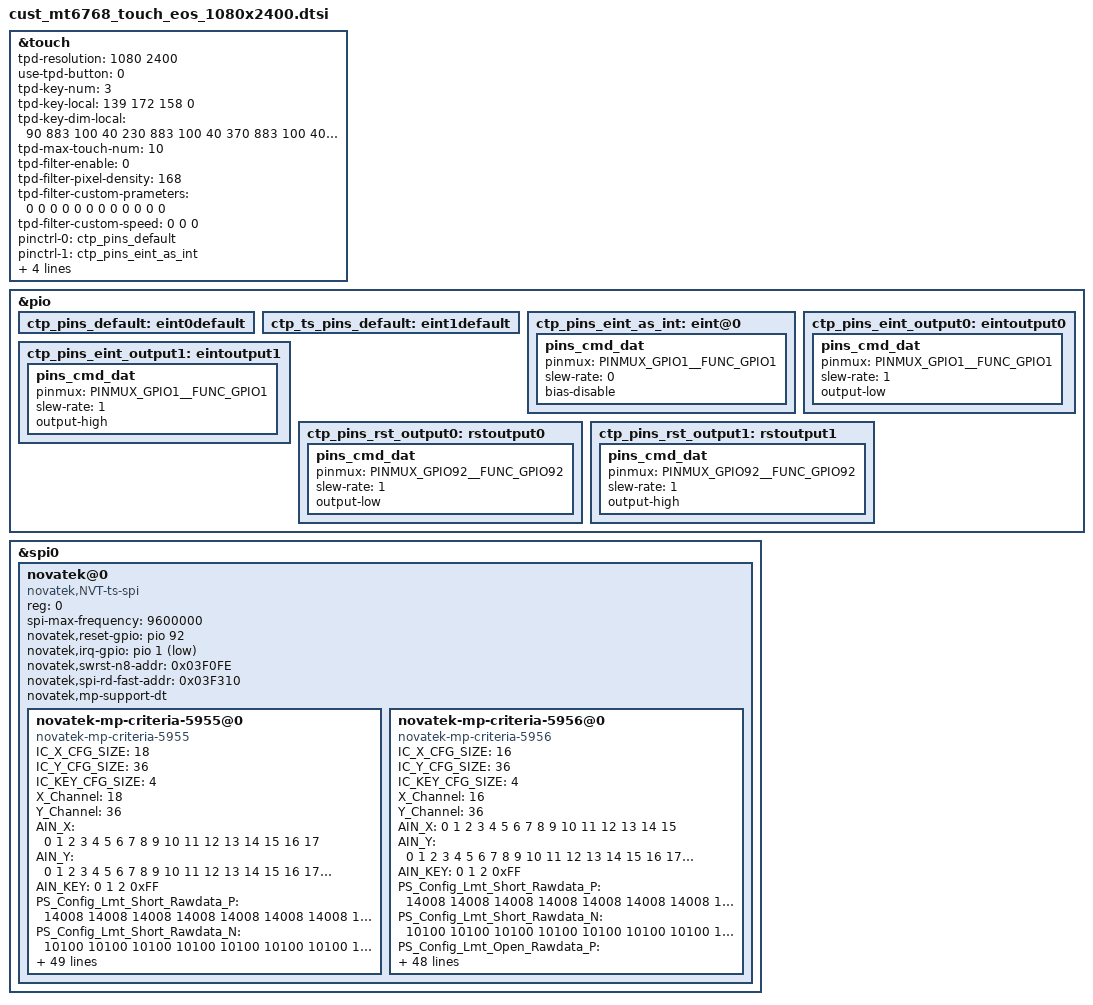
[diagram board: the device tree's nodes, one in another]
/*
 * Copyright (c) 2019 MediaTek Inc.
 *
 * This program is free software; you can redistribute it and/or modify
 * it under the terms of the GNU General Public License version 2 as
 * published by the Free Software Foundation.
 *
 * This program is distributed in the hope that it will be useful,
 * but WITHOUT ANY WARRANTY; without even the implied warranty of
 * MERCHANTABILITY or FITNESS FOR A PARTICULAR PURPOSE.  See the
 * GNU General Public License for more details.
 */
/* TOUCH start */

&touch {
	tpd-resolution = <1080 2400>;
	use-tpd-button = <0>;
	tpd-key-num = <3>;
	tpd-key-local= <139 172 158 0>;
	tpd-key-dim-local = <90 883 100 40 230
				883 100 40 370 883 100 40 0 0 0 0>;
	tpd-max-touch-num = <10>;
	tpd-filter-enable = <0>;
	tpd-filter-pixel-density = <168>;
	tpd-filter-custom-prameters = <0 0 0 0 0 0 0 0 0 0 0 0>;
	tpd-filter-custom-speed = <0 0 0>;
	pinctrl-names = "default", "state_eint_as_int",
		"state_eint_output0", "state_eint_output1",
		"state_rst_output0", "state_rst_output1";
	pinctrl-0 = <&ctp_pins_default>;
	pinctrl-1 = <&ctp_pins_eint_as_int>;
	pinctrl-2 = <&ctp_pins_eint_output0>;
	pinctrl-3 = <&ctp_pins_eint_output1>;
	pinctrl-4 = <&ctp_pins_rst_output0>;
	pinctrl-5 = <&ctp_pins_rst_output1>;
	status = "okay";
};
&pio {
	ctp_pins_default: eint0default {
	};
	ctp_ts_pins_default: eint1default {
	};
	ctp_pins_eint_as_int: eint@0 {
		pins_cmd_dat {
			pinmux = <PINMUX_GPIO1__FUNC_GPIO1>;
			slew-rate = <0>;
			bias-disable;
		};
	};
	ctp_pins_eint_output0: eintoutput0 {
		pins_cmd_dat {
			pinmux = <PINMUX_GPIO1__FUNC_GPIO1>;
			slew-rate = <1>;
			output-low;
		};
	};
	ctp_pins_eint_output1: eintoutput1 {
		pins_cmd_dat {
			pinmux = <PINMUX_GPIO1__FUNC_GPIO1>;
			slew-rate = <1>;
			output-high;
	};
	};
	ctp_pins_rst_output0: rstoutput0 {
		pins_cmd_dat {
				pinmux = <PINMUX_GPIO92__FUNC_GPIO92>;
				slew-rate = <1>;
				output-low;
			};
	};
	ctp_pins_rst_output1: rstoutput1 {
		pins_cmd_dat {
				pinmux = <PINMUX_GPIO92__FUNC_GPIO92>;
				slew-rate = <1>;
				output-high;
		};
	};

};

&spi0 {
	novatek@0 {
		compatible = "novatek,NVT-ts-spi","focaltech8719P,FTS-ts-spi";
		reg = <0>; //Same as CS ID
		status = "ok";

		spi-max-frequency = <9600000>;	//4800000,9600000,15000000,19200000
		novatek,reset-gpio = <&pio 92 0x00>;
		novatek,irq-gpio = <&pio 1 0x2001>;

		/* 525 */
		//novatek,swrst-n8-addr = <0x01F01A>;

		/* 672A, 525B, 675, 526, 672C */
		novatek,swrst-n8-addr = <0x03F0FE>;
		novatek,spi-rd-fast-addr = <0x03F310>;

		/* MP */
		novatek,mp-support-dt;

		/*for Xiaomi K19A 672C TM6.497" Module*/
		novatek-mp-criteria-5955@0 {
			#address-cells = <1>;
			#size-cells = <0>;
			compatible = "novatek-mp-criteria-5955";

			/* MP Config */
			IC_X_CFG_SIZE = <18>;
			IC_Y_CFG_SIZE = <36>;
			IC_KEY_CFG_SIZE = <4>;
			X_Channel = <18>;
			Y_Channel = <36>;
			AIN_X = <0 1 2 3 4 5 6 7 8 9 10 11 12 13 14 15 16 17>;
			AIN_Y = <0 1 2 3 4 5 6 7 8 9 10 11 12 13 14 15 16 17 18 19 20 21 22 23 24 25 26 27 28 29 30 31 32 33 34 35>;
			//AIN_X = <0 1 2 3 4 5 6 7 8 9 10 11 12 13 14 15 16 17 18 19 20 21 22 23 24 25 26 27 28 29 30 31>;
			//AIN_Y = <0 1 2 3 4 5 6 7 8 9 10 11 12 13 14 15 16 17 18 19 20 21 22 23 24 25 26 27 28 29 30 31 32 33 34 35 36 37 38 39 40 41 42 43 44 45 46 47 48 49>;
			AIN_KEY = <0 1 2 0xFF>;

			/* Huaqin modify for HQ-152282 by zhangjiangbin at 2021/08/23 start */

			/* MP Criteria */
			PS_Config_Lmt_Short_Rawdata_P = <
				14008	14008	14008	14008	14008	14008	14008	14008	14008	14008	14008	14008	14008	14008	14008	14008	14008	14008
				14008	14008	14008	14008	14008	14008	14008	14008	14008	14008	14008	14008	14008	14008	14008	14008	14008	14008
				14008	14008	14008	14008	14008	14008	14008	14008	14008	14008	14008	14008	14008	14008	14008	14008	14008	14008
				14008	14008	14008	14008	14008	14008	14008	14008	14008	14008	14008	14008	14008	14008	14008	14008	14008	14008
				14008	14008	14008	14008	14008	14008	14008	14008	14008	14008	14008	14008	14008	14008	14008	14008	14008	14008
				14008	14008	14008	14008	14008	14008	14008	14008	14008	14008	14008	14008	14008	14008	14008	14008	14008	14008
				14008	14008	14008	14008	14008	14008	14008	14008	14008	14008	14008	14008	14008	14008	14008	14008	14008	14008
				14008	14008	14008	14008	14008	14008	14008	14008	14008	14008	14008	14008	14008	14008	14008	14008	14008	14008
				14008	14008	14008	14008	14008	14008	14008	14008	14008	14008	14008	14008	14008	14008	14008	14008	14008	14008
				14008	14008	14008	14008	14008	14008	14008	14008	14008	14008	14008	14008	14008	14008	14008	14008	14008	14008
				14008	14008	14008	14008	14008	14008	14008	14008	14008	14008	14008	14008	14008	14008	14008	14008	14008	14008
				14008	14008	14008	14008	14008	14008	14008	14008	14008	14008	14008	14008	14008	14008	14008	14008	14008	14008
				14008	14008	14008	14008	14008	14008	14008	14008	14008	14008	14008	14008	14008	14008	14008	14008	14008	14008
				14008	14008	14008	14008	14008	14008	14008	14008	14008	14008	14008	14008	14008	14008	14008	14008	14008	14008
				14008	14008	14008	14008	14008	14008	14008	14008	14008	14008	14008	14008	14008	14008	14008	14008	14008	14008
				14008	14008	14008	14008	14008	14008	14008	14008	14008	14008	14008	14008	14008	14008	14008	14008	14008	14008
				14008	14008	14008	14008	14008	14008	14008	14008	14008	14008	14008	14008	14008	14008	14008	14008	14008	14008
				14008	14008	14008	14008	14008	14008	14008	14008	14008	14008	14008	14008	14008	14008	14008	14008	14008	14008
				14008	14008	14008	14008	14008	14008	14008	14008	14008	14008	14008	14008	14008	14008	14008	14008	14008	14008
				14008	14008	14008	14008	14008	14008	14008	14008	14008	14008	14008	14008	14008	14008	14008	14008	14008	14008
				14008	14008	14008	14008	14008	14008	14008	14008	14008	14008	14008	14008	14008	14008	14008	14008	14008	14008
				14008	14008	14008	14008	14008	14008	14008	14008	14008	14008	14008	14008	14008	14008	14008	14008	14008	14008
				14008	14008	14008	14008	14008	14008	14008	14008	14008	14008	14008	14008	14008	14008	14008	14008	14008	14008
				14008	14008	14008	14008	14008	14008	14008	14008	14008	14008	14008	14008	14008	14008	14008	14008	14008	14008
				14008	14008	14008	14008	14008	14008	14008	14008	14008	14008	14008	14008	14008	14008	14008	14008	14008	14008
				14008	14008	14008	14008	14008	14008	14008	14008	14008	14008	14008	14008	14008	14008	14008	14008	14008	14008
				14008	14008	14008	14008	14008	14008	14008	14008	14008	14008	14008	14008	14008	14008	14008	14008	14008	14008
				14008	14008	14008	14008	14008	14008	14008	14008	14008	14008	14008	14008	14008	14008	14008	14008	14008	14008
				14008	14008	14008	14008	14008	14008	14008	14008	14008	14008	14008	14008	14008	14008	14008	14008	14008	14008
				14008	14008	14008	14008	14008	14008	14008	14008	14008	14008	14008	14008	14008	14008	14008	14008	14008	14008
				14008	14008	14008	14008	14008	14008	14008	14008	14008	14008	14008	14008	14008	14008	14008	14008	14008	14008
				14008	14008	14008	14008	14008	14008	14008	14008	14008	14008	14008	14008	14008	14008	14008	14008	14008	14008
				14008	14008	14008	14008	14008	14008	14008	14008	14008	14008	14008	14008	14008	14008	14008	14008	14008	14008
				14008	14008	14008	14008	14008	14008	14008	14008	14008	14008	14008	14008	14008	14008	14008	14008	14008	14008
				14008	14008	14008	14008	14008	14008	14008	14008	14008	14008	14008	14008	14008	14008	14008	14008	14008	14008
				14008	14008	14008	14008	14008	14008	14008	14008	14008	14008	14008	14008	14008	14008	14008	14008	14008	14008
				14008 14008 14008>;

			PS_Config_Lmt_Short_Rawdata_N = <
				10100	10100	10100	10100	10100	10100	10100	10100	10100	10100	10100	10100	10100	10100	10100	10100	10100	10100
				10100	10100	10100	10100	10100	10100	10100	10100	10100	10100	10100	10100	10100	10100	10100	10100	10100	10100
				10100	10100	10100	10100	10100	10100	10100	10100	10100	10100	10100	10100	10100	10100	10100	10100	10100	10100
				10100	10100	10100	10100	10100	10100	10100	10100	10100	10100	10100	10100	10100	10100	10100	10100	10100	10100
				10100	10100	10100	10100	10100	10100	10100	10100	10100	10100	10100	10100	10100	10100	10100	10100	10100	10100
				10100	10100	10100	10100	10100	10100	10100	10100	10100	10100	10100	10100	10100	10100	10100	10100	10100	10100
				10100	10100	10100	10100	10100	10100	10100	10100	10100	10100	10100	10100	10100	10100	10100	10100	10100	10100
				10100	10100	10100	10100	10100	10100	10100	10100	10100	10100	10100	10100	10100	10100	10100	10100	10100	10100
				10100	10100	10100	10100	10100	10100	10100	10100	10100	10100	10100	10100	10100	10100	10100	10100	10100	10100
				10100	10100	10100	10100	10100	10100	10100	10100	10100	10100	10100	10100	10100	10100	10100	10100	10100	10100
				10100	10100	10100	10100	10100	10100	10100	10100	10100	10100	10100	10100	10100	10100	10100	10100	10100	10100
				10100	10100	10100	10100	10100	10100	10100	10100	10100	10100	10100	10100	10100	10100	10100	10100	10100	10100
				10100	10100	10100	10100	10100	10100	10100	10100	10100	10100	10100	10100	10100	10100	10100	10100	10100	10100
				10100	10100	10100	10100	10100	10100	10100	10100	10100	10100	10100	10100	10100	10100	10100	10100	10100	10100
				10100	10100	10100	10100	10100	10100	10100	10100	10100	10100	10100	10100	10100	10100	10100	10100	10100	10100
				10100	10100	10100	10100	10100	10100	10100	10100	10100	10100	10100	10100	10100	10100	10100	10100	10100	10100
				10100	10100	10100	10100	10100	10100	10100	10100	10100	10100	10100	10100	10100	10100	10100	10100	10100	10100
				10100	10100	10100	10100	10100	10100	10100	10100	10100	10100	10100	10100	10100	10100	10100	10100	10100	10100
				10100	10100	10100	10100	10100	10100	10100	10100	10100	10100	10100	10100	10100	10100	10100	10100	10100	10100
				10100	10100	10100	10100	10100	10100	10100	10100	10100	10100	10100	10100	10100	10100	10100	10100	10100	10100
				10100	10100	10100	10100	10100	10100	10100	10100	10100	10100	10100	10100	10100	10100	10100	10100	10100	10100
				10100	10100	10100	10100	10100	10100	10100	10100	10100	10100	10100	10100	10100	10100	10100	10100	10100	10100
				10100	10100	10100	10100	10100	10100	10100	10100	10100	10100	10100	10100	10100	10100	10100	10100	10100	10100
				10100	10100	10100	10100	10100	10100	10100	10100	10100	10100	10100	10100	10100	10100	10100	10100	10100	10100
				10100	10100	10100	10100	10100	10100	10100	10100	10100	10100	10100	10100	10100	10100	10100	10100	10100	10100
				10100	10100	10100	10100	10100	10100	10100	10100	10100	10100	10100	10100	10100	10100	10100	10100	10100	10100
				10100	10100	10100	10100	10100	10100	10100	10100	10100	10100	10100	10100	10100	10100	10100	10100	10100	10100
				10100	10100	10100	10100	10100	10100	10100	10100	10100	10100	10100	10100	10100	10100	10100	10100	10100	10100
				10100	10100	10100	10100	10100	10100	10100	10100	10100	10100	10100	10100	10100	10100	10100	10100	10100	10100
				10100	10100	10100	10100	10100	10100	10100	10100	10100	10100	10100	10100	10100	10100	10100	10100	10100	10100
				10100	10100	10100	10100	10100	10100	10100	10100	10100	10100	10100	10100	10100	10100	10100	10100	10100	10100
				10100	10100	10100	10100	10100	10100	10100	10100	10100	10100	10100	10100	10100	10100	10100	10100	10100	10100
				10100	10100	10100	10100	10100	10100	10100	10100	10100	10100	10100	10100	10100	10100	10100	10100	10100	10100
				10100	10100	10100	10100	10100	10100	10100	10100	10100	10100	10100	10100	10100	10100	10100	10100	10100	10100
				10100	10100	10100	10100	10100	10100	10100	10100	10100	10100	10100	10100	10100	10100	10100	10100	10100	10100
				10100	10100	10100	10100	10100	10100	10100	10100	10100	10100	10100	10100	10100	10100	10100	10100	10100	10100
				10000 10000 10000>;

			PS_Config_Lmt_Open_Rawdata_P = <
				2959	2973	3073	3136	3161	3193	3234	3264	3259	3329	3305	3267	3207	3171	3127	3053	2933	2851
				2913	3001	3071	3136	3165	3192	3229	3263	3291	3347	3313	3273	3217	3182	3145	3073	2982	2895
				2994	3054	3119	3192	3224	3243	3284	3319	3354	3389	3368	3312	3249	3206	3171	3081	2996	2896
				3011	3042	3120	3215	3259	3290	3346	3392	3434	3462	3393	3347	3277	3232	3183	3088	3001	2982
				3046	3070	3144	3239	3276	3297	3332	3375	3473	3501	3421	3371	3285	3242	3182	3078	2987	2986
				3040	3077	3151	3249	3302	3337	3382	3437	3523	3501	3434	3397	3319	3280	3220	3117	3029	3050
				3084	3109	3186	3277	3325	3350	3389	3432	3546	3595	3525	3473	3393	3332	3253	3143	3033	3038
				3077	3119	3213	3306	3372	3406	3446	3469	3593	3591	3519	3469	3397	3343	3262	3158	3031	3085
				3147	3179	3266	3361	3427	3446	3487	3544	3651	3649	3584	3525	3451	3393	3305	3192	3108	3103
				3150	3197	3283	3383	3459	3484	3530	3593	3682	3683	3627	3570	3497	3446	3354	3235	3152	3173
				3201	3243	3322	3423	3495	3518	3519	3630	3729	3696	3627	3579	3497	3444	3333	3192	3136	3137
				3211	3271	3357	3463	3542	3570	3623	3684	3756	3696	3637	3593	3522	3480	3378	3276	3189	3208
				3257	3306	3397	3493	3579	3609	3666	3726	3815	3753	3701	3652	3584	3521	3409	3305	3201	3197
				3248	3312	3411	3507	3602	3637	3704	3761	3830	3773	3719	3673	3606	3553	3430	3337	3245	3264
				3313	3369	3452	3544	3638	3638	3733	3782	3865	3844	3785	3725	3648	3596	3446	3368	3281	3263
				3285	3367	3459	3556	3658	3707	3774	3831	3892	3845	3795	3742	3676	3620	3509	3395	3309	3322
				3334	3409	3480	3575	3670	3726	3788	3838	3903	3882	3824	3771	3698	3644	3529	3413	3313	3312
				3329	3414	3490	3591	3686	3768	3847	3907	3952	3865	3808	3756	3690	3620	3530	3417	3329	3351
				3399	3325	3358	3414	3434	3507	3570	3627	3683	3722	3690	3647	3567	3502	3486	3442	3395	3367
				3369	3327	3361	3421	3469	3526	3595	3659	3721	3724	3675	3630	3563	3523	3490	3445	3399	3385
				3428	3372	3404	3448	3494	3540	3602	3652	3701	3747	3703	3651	3595	3557	3521	3472	3421	3389
				3388	3361	3406	3437	3519	3571	3647	3697	3752	3787	3718	3669	3586	3582	3544	3495	3444	3432
				3459	3418	3456	3511	3558	3592	3652	3691	3735	3791	3731	3683	3630	3600	3558	3504	3446	3417
				3442	3430	3466	3537	3584	3628	3700	3749	3802	3840	3767	3718	3675	3649	3612	3553	3500	3477
				3488	3453	3491	3551	3595	3631	3689	3731	3773	3859	3794	3743	3696	3662	3620	3568	3504	3472
				3453	3452	3479	3572	3626	3675	3740	3791	3847	3837	3756	3682	3666	3638	3606	3557	3498	3470
				3511	3487	3547	3602	3644	3676	3743	3781	3834	3833	3764	3725	3687	3656	3624	3564	3511	3463
				3452	3449	3525	3582	3635	3673	3745	3788	3851	3852	3766	3729	3694	3668	3634	3584	3535	3507
				3507	3476	3560	3619	3659	3691	3754	3792	3852	3859	3767	3747	3694	3665	3623	3565	3507	3453
				3462	3477	3547	3616	3661	3700	3775	3816	3879	3859	3784	3745	3698	3670	3637	3581	3522	3495
				3488	3490	3565	3626	3669	3705	3764	3801	3852	3865	3805	3766	3729	3693	3658	3606	3532	3490
				3476	3500	3586	3641	3689	3736	3798	3840	3907	3883	3810	3774	3739	3711	3680	3635	3560	3549
				3491	3519	3610	3658	3704	3738	3799	3833	3892	3847	3805	3766	3729	3698	3672	3623	3551	3522
				3437	3551	3662	3725	3780	3829	3907	3952	4018	3976	3911	3868	3823	3789	3756	3698	3609	3518
				3341	3605	3710	3767	3813	3845	3906	3948	4009	4013	3957	3925	3865	3833	3788	3724	3610	3372
				3152	3546	3703	3778	3827	3873	3949	4006	4075	3992	3935	3903	3847	3813	3780	3725	3584	3253
				5120 5120 5120>;

			PS_Config_Lmt_Open_Rawdata_N = <
				1268	1274	1317	1344	1354	1368	1386	1399	1396	1426	1416	1400	1374	1359	1340	1308	1257	1222
				1248	1286	1316	1344	1356	1368	1384	1398	1410	1434	1420	1402	1378	1363	1348	1317	1278	1240
				1283	1309	1336	1368	1381	1390	1407	1422	1437	1452	1443	1419	1392	1374	1359	1320	1284	1241
				1290	1303	1337	1378	1396	1410	1434	1453	1471	1483	1454	1434	1404	1385	1364	1323	1286	1278
				1305	1315	1347	1388	1404	1413	1428	1446	1488	1500	1466	1444	1408	1389	1363	1319	1280	1279
				1303	1318	1350	1392	1415	1430	1449	1473	1510	1500	1471	1456	1422	1405	1380	1336	1298	1307
				1321	1332	1365	1404	1425	1435	1452	1471	1519	1540	1510	1488	1454	1428	1394	1347	1300	1302
				1318	1336	1377	1417	1445	1459	1477	1486	1540	1539	1508	1486	1456	1432	1398	1353	1299	1322
				1348	1362	1399	1440	1468	1477	1494	1519	1564	1564	1536	1510	1479	1454	1416	1368	1332	1330
				1350	1370	1407	1450	1482	1493	1513	1540	1578	1578	1554	1530	1498	1477	1437	1386	1351	1360
				1372	1390	1423	1467	1498	1507	1508	1555	1598	1584	1554	1534	1498	1476	1428	1368	1344	1344
				1376	1402	1438	1484	1518	1530	1552	1579	1609	1584	1558	1540	1509	1491	1447	1404	1366	1375
				1396	1417	1456	1497	1534	1546	1571	1597	1635	1608	1586	1565	1536	1509	1461	1416	1372	1370
				1392	1419	1462	1503	1543	1558	1587	1612	1641	1617	1594	1574	1545	1522	1470	1430	1390	1399
				1420	1444	1479	1519	1559	1559	1600	1621	1656	1647	1622	1596	1563	1541	1477	1443	1406	1398
				1408	1443	1482	1524	1567	1588	1617	1642	1668	1648	1626	1603	1575	1551	1504	1455	1418	1423
				1429	1461	1491	1532	1573	1597	1623	1645	1672	1663	1639	1616	1585	1561	1512	1462	1420	1419
				1426	1463	1495	1539	1579	1615	1648	1674	1693	1656	1632	1609	1581	1551	1513	1464	1426	1436
				1456	1425	1439	1463	1471	1503	1530	1554	1578	1595	1581	1563	1528	1501	1494	1475	1455	1443
				1444	1426	1440	1466	1486	1511	1540	1568	1594	1596	1575	1555	1527	1510	1495	1476	1456	1450
				1469	1445	1459	1477	1497	1517	1543	1565	1586	1606	1587	1564	1540	1524	1509	1488	1466	1452
				1452	1440	1459	1473	1508	1530	1563	1584	1608	1623	1593	1572	1537	1535	1519	1498	1476	1471
				1482	1465	1481	1504	1525	1539	1565	1582	1600	1624	1599	1578	1555	1543	1525	1501	1477	1464
				1475	1470	1485	1516	1536	1555	1585	1606	1629	1645	1614	1593	1575	1564	1548	1522	1500	1490
				1495	1480	1496	1522	1540	1556	1581	1599	1617	1654	1626	1604	1584	1569	1551	1529	1501	1488
				1480	1479	1491	1531	1554	1575	1603	1624	1648	1644	1609	1578	1571	1559	1545	1524	1499	1487
				1504	1494	1520	1543	1561	1575	1604	1620	1643	1642	1613	1596	1580	1567	1553	1527	1504	1484
				1479	1478	1510	1535	1558	1574	1605	1623	1650	1651	1614	1598	1583	1572	1557	1536	1515	1503
				1503	1489	1525	1551	1568	1582	1609	1625	1651	1654	1614	1606	1583	1570	1552	1528	1503	1480
				1483	1490	1520	1549	1569	1585	1618	1635	1662	1654	1621	1605	1585	1573	1558	1534	1509	1498
				1495	1495	1528	1554	1572	1588	1613	1629	1651	1656	1630	1614	1598	1582	1567	1545	1513	1495
				1489	1500	1537	1560	1581	1601	1627	1645	1674	1664	1633	1617	1602	1590	1577	1558	1525	1521
				1496	1508	1547	1567	1587	1602	1628	1642	1668	1648	1630	1614	1598	1585	1573	1552	1522	1509
				1473	1522	1569	1596	1620	1641	1674	1693	1722	1704	1676	1657	1638	1624	1609	1585	1546	1507
				1432	1545	1590	1614	1634	1648	1674	1692	1718	1720	1696	1682	1656	1642	1623	1596	1547	1445
				1351	1519	1587	1619	1640	1660	1692	1717	1746	1711	1686	1672	1648	1634	1620	1596	1536	1394
				(-511) (-511) (-511)>;

			PS_Config_Lmt_FW_Rawdata_P = <
				1118	1111	1118	1113	1117	1113	1111	1122	1115	1138	1115	1113	1108	1092	1101	1093	1106	1101
				1103	1118	1127	1117	1121	1115	1113	1125	1106	1118	1110	1131	1129	1131	1131	1125	1114	1093
				1117	1107	1110	1110	1113	1106	1107	1117	1121	1111	1107	1113	1115	1114	1117	1108	1134	1110
				1099	1125	1148	1145	1125	1139	1139	1100	1107	1120	1115	1113	1111	1111	1106	1117	1115	1117
				1122	1114	1117	1121	1111	1122	1121	1113	1101	1113	1115	1125	1124	1115	1117	1118	1122	1111
				1103	1117	1125	1121	1128	1122	1134	1090	1097	1108	1100	1107	1108	1113	1113	1107	1110	1113
				1103	1108	1115	1114	1122	1122	1117	1115	1115	1127	1115	1114	1111	1114	1117	1117	1125	1118
				1107	1125	1132	1128	1113	1131	1118	1106	1110	1118	1099	1093	1094	1092	1100	1128	1122	1120
				1108	1108	1107	1120	1107	1129	1125	1134	1120	1107	1094	1096	1111	1120	1122	1114	1122	1103
				1129	1108	1115	1122	1118	1132	1132	1103	1108	1115	1100	1120	1128	1129	1125	1129	1122	1097
				1108	1094	1100	1089	1086	1100	1093	1113	1111	1120	1108	1114	1121	1118	1115	1120	1120	1113
				1108	1127	1136	1131	1135	1099	1115	1129	1139	1108	1117	1113	1125	1132	1128	1127	1125	1117
				1122	1122	1125	1127	1120	1120	1122	1093	1093	1096	1143	1136	1122	1122	1120	1113	1111	1122
				1124	1121	1132	1122	1127	1114	1124	1118	1125	1136	1101	1099	1117	1125	1111	1132	1129	1127
				1120	1106	1107	1113	1101	1125	1128	1127	1111	1108	1131	1124	1122	1127	1127	1115	1117	1103
				1120	1096	1099	1110	1107	1120	1120	1110	1128	1106	1124	1125	1125	1129	1117	1132	1134	1121
				1124	1121	1129	1131	1124	1115	1118	1107	1108	1110	1106	1111	1111	1101	1104	1128	1120	1125
				1113	1121	1125	1122	1118	1103	1106	1125	1104	1117	1104	1104	1108	1111	1135	1136	1141	1131
				1131	1136	1117	1118	1118	1131	1132	1113	1122	1117	1111	1120	1111	1113	1114	1125	1127	1106
				1111	1120	1124	1118	1117	1134	1134	1118	1106	1125	1117	1128	1124	1096	1103	1097	1101	1132
				1121	1114	1115	1108	1117	1110	1110	1104	1115	1114	1106	1117	1115	1128	1111	1113	1113	1107
				1107	1096	1097	1100	1110	1113	1121	1115	1118	1121	1118	1117	1113	1128	1121	1114	1124	1118
				1113	1110	1114	1115	1108	1115	1120	1118	1114	1117	1115	1115	1120	1107	1108	1113	1115	1125
				1122	1113	1104	1107	1107	1110	1120	1117	1127	1145	1117	1094	1092	1121	1104	1117	1117	1111
				1104	1117	1115	1122	1117	1108	1135	1138	1134	1117	1118	1115	1117	1128	1124	1128	1129	1114
				1115	1114	1113	1113	1115	1120	1108	1108	1115	1100	1094	1129	1136	1121	1124	1127	1132	1096
				1122	1106	1107	1104	1103	1094	1114	1115	1128	1139	1117	1120	1114	1103	1101	1103	1096	1122
				1124	1115	1124	1115	1127	1121	1131	1121	1103	1110	1104	1115	1120	1118	1121	1120	1113	1106
				1129	1101	1104	1111	1101	1113	1106	1103	1128	1107	1124	1125	1121	1127	1124	1124	1124	1113
				1134	1120	1096	1127	1096	1128	1092	1092	1120	1120	1129	1108	1115	1111	1113	1115	1113	1111
				1127	1103	1117	1106	1108	1110	1113	1110	1107	1120	1111	1108	1104	1107	1111	1108	1106	1117
				1120	1115	1117	1121	1121	1117	1117	1107	1114	1113	1111	1090	1104	1101	1108	1099	1120	1125
				1131	1097	1100	1090	1110	1092	1106	1090	1124	1106	1121	1107	1115	1122	1122	1108	1122	1115
				1100	1121	1138	1124	1131	1125	1129	1132	1115	1125	1111	1135	1125	1127	1124	1135	1114	1118
				1129	1138	1120	1142	1117	1141	1110	1136	1117	1124	1110	1121	1108	1110	1110	1120	1100	1121
				1124	1117	1127	1124	1122	1135	1094	1113	1120	1132	1111	1110	1118	1103	1125	1121	1132	1125
				2560 2560 2560>;

			PS_Config_Lmt_FW_Rawdata_N = <
				479	476	479	477	478	477	476	481	478	487	478	477	475	468	472	468	474	472
				472	479	483	478	480	478	477	482	474	479	475	484	484	484	484	482	477	468
				478	474	475	475	477	474	474	478	480	476	474	477	478	477	478	475	486	475
				471	482	492	490	482	488	488	471	474	480	478	477	476	476	474	478	478	478
				481	477	478	480	476	481	480	477	472	477	478	482	481	478	478	479	481	476
				472	478	482	480	483	481	486	467	470	475	471	474	475	477	477	474	475	477
				472	475	478	477	481	481	478	478	478	483	478	477	476	477	478	478	482	479
				474	482	485	483	477	484	479	474	475	479	471	468	469	468	471	483	481	480
				475	475	474	480	474	484	482	486	480	474	469	469	476	480	481	477	481	472
				484	475	478	481	479	485	485	472	475	478	471	480	483	484	482	484	481	470
				475	469	471	466	465	471	468	477	476	480	475	477	480	479	478	480	480	477
				475	483	487	484	486	471	478	484	488	475	478	477	482	485	483	483	482	478
				481	481	482	483	480	480	481	468	468	469	490	487	481	481	480	477	476	481
				481	480	485	481	483	477	481	479	482	487	472	471	478	482	476	485	484	483
				480	474	474	477	472	482	483	483	476	475	484	481	481	483	483	478	478	472
				480	469	471	475	474	480	480	475	483	474	481	482	482	484	478	485	486	480
				481	480	484	484	481	478	479	474	475	475	474	476	476	472	473	483	480	482
				477	480	482	481	479	472	474	482	473	478	473	473	475	476	486	487	489	484
				484	487	478	479	479	484	485	477	481	478	476	480	476	477	477	482	483	474
				476	480	481	479	478	486	486	479	474	482	478	483	481	469	472	470	472	485
				480	477	478	475	478	475	475	473	478	477	474	478	478	483	476	477	477	474
				474	469	470	471	475	477	480	478	479	480	479	478	477	483	480	477	481	479
				477	475	477	478	475	478	480	479	477	478	478	478	480	474	475	477	478	482
				481	477	473	474	474	475	480	478	483	490	478	469	468	480	473	478	478	476
				473	478	478	481	478	475	486	487	486	478	479	478	478	483	481	483	484	477
				478	477	477	477	478	480	475	475	478	471	469	484	487	480	481	483	485	469
				481	474	474	473	472	469	477	478	483	488	478	480	477	472	472	472	469	481
				481	478	481	478	483	480	484	480	472	475	473	478	480	479	480	480	477	474
				484	472	473	476	472	477	474	472	483	474	481	482	480	483	481	481	481	477
				486	480	469	483	469	483	468	468	480	480	484	475	478	476	477	478	477	476
				483	472	478	474	475	475	477	475	474	480	476	475	473	474	476	475	474	478
				480	478	478	480	480	478	478	474	477	477	476	467	473	472	475	471	480	482
				484	470	471	467	475	468	474	467	481	474	480	474	478	481	481	475	481	478
				471	480	487	481	484	482	484	485	478	482	476	486	482	483	481	486	477	479
				484	487	480	489	478	489	475	487	478	481	475	480	475	475	475	480	471	480
				481	478	483	481	481	486	469	477	480	485	476	475	479	472	482	480	485	482
				240 240 240>;

			PS_Config_Lmt_FW_CC_P = <
				52	52	52	52	52	52	52	53	55	55	53	53	53	53	53	53	53	53
				52	52	52	52	52	52	52	52	55	55	52	52	52	52	52	52	52	53
				52	52	52	52	52	52	52	52	55	53	52	52	52	52	52	52	52	52
				53	52	52	52	52	52	52	53	55	53	53	52	52	52	52	52	52	53
				52	52	52	52	52	52	52	52	53	53	52	52	52	52	52	52	52	53
				53	52	52	52	52	53	52	53	55	55	53	52	52	52	52	52	52	53
				53	52	52	52	52	52	52	52	53	53	53	52	52	52	52	52	52	53
				53	52	53	53	53	53	53	53	55	55	52	52	52	52	52	52	52	53
				52	52	52	52	52	52	52	52	53	55	53	53	53	52	52	52	52	53
				53	52	52	52	52	53	52	53	55	55	53	53	53	53	53	52	52	53
				52	52	52	52	52	52	52	53	53	55	53	53	52	52	52	52	52	53
				53	52	52	53	53	53	53	53	55	55	53	53	52	52	52	52	52	53
				53	52	52	52	52	53	52	53	55	53	53	53	53	52	53	52	52	53
				53	52	52	53	53	53	53	53	55	53	53	53	52	52	52	52	52	53
				52	52	52	52	52	52	52	53	55	53	53	53	53	53	53	53	53	53
				53	53	53	53	53	53	53	55	56	53	53	53	53	53	53	52	52	53
				53	52	52	52	52	53	53	53	55	53	53	53	53	53	52	52	52	53
				53	52	53	53	53	53	53	53	56	53	52	53	53	52	52	52	52	53
				53	52	52	52	52	52	52	52	52	56	53	53	53	53	53	52	52	53
				53	52	52	52	52	53	53	53	53	56	53	53	53	53	53	53	52	53
				53	52	52	52	52	52	52	52	52	55	53	53	53	52	52	52	52	53
				53	53	53	53	53	53	53	53	53	56	53	53	53	52	53	52	52	53
				53	52	52	52	52	52	53	53	53	55	53	53	53	52	53	52	52	53
				53	53	53	53	53	53	53	53	53	55	53	53	53	53	53	53	53	53
				53	52	52	52	52	52	53	53	55	55	53	53	53	53	53	53	53	53
				53	53	53	53	53	53	53	53	55	56	53	53	53	53	53	53	53	53
				53	52	53	53	53	53	53	53	55	55	53	53	53	53	53	53	53	53
				55	53	53	53	53	53	53	53	56	55	53	53	53	53	53	53	53	53
				53	52	53	52	53	52	53	53	53	55	53	53	53	53	53	53	53	53
				53	53	53	53	53	53	53	53	55	55	53	53	53	53	53	53	53	53
				53	53	53	52	53	52	53	53	55	55	53	53	53	53	53	53	53	55
				55	53	53	53	53	53	53	53	56	55	53	53	53	53	53	53	53	55
				53	53	53	53	53	53	53	53	55	55	53	53	53	53	53	53	53	55
				55	53	53	53	53	53	53	53	56	56	53	53	53	53	53	53	53	53
				52	52	53	52	52	52	53	52	55	55	53	53	53	53	53	53	53	53
				53	53	53	53	53	53	53	55	56	56	55	53	53	53	53	53	53	53
				314 314 314>;

			PS_Config_Lmt_FW_CC_N = <
				23	23	23	23	23	23	23	24	24	24	24	24	24	24	24	24	24	24
				23	23	23	23	23	23	23	23	24	24	23	23	23	23	23	23	23	24
				23	23	23	23	23	23	23	23	24	24	23	23	23	23	23	23	23	23
				24	23	23	23	23	23	23	24	24	24	24	23	23	23	23	23	23	24
				23	23	23	23	23	23	23	23	24	24	23	23	23	23	23	23	23	24
				24	23	23	23	23	24	23	24	24	24	24	23	23	23	23	23	23	24
				24	23	23	23	23	23	23	23	24	24	24	23	23	23	23	23	23	24
				24	23	24	24	24	24	24	24	24	24	23	23	23	23	23	23	23	24
				23	23	23	23	23	23	23	23	24	24	24	24	24	23	23	23	23	24
				24	23	23	23	23	24	23	24	24	24	24	24	24	24	24	23	23	24
				23	23	23	23	23	23	23	24	24	24	24	24	23	23	23	23	23	24
				24	23	23	24	24	24	24	24	24	24	24	24	23	23	23	23	23	24
				24	23	23	23	23	24	23	24	24	24	24	24	24	23	24	23	23	24
				24	23	23	24	24	24	24	24	24	24	24	24	23	23	23	23	23	24
				23	23	23	23	23	23	23	24	24	24	24	24	24	24	24	24	24	24
				24	24	24	24	24	24	24	24	25	24	24	24	24	24	24	23	23	24
				24	23	23	23	23	24	24	24	24	24	24	24	24	24	23	23	23	24
				24	23	24	24	24	24	24	24	25	24	23	24	24	23	23	23	23	24
				24	23	23	23	23	23	23	23	23	25	24	24	24	24	24	23	23	24
				24	23	23	23	23	24	24	24	24	25	24	24	24	24	24	24	23	24
				24	23	23	23	23	23	23	23	23	24	24	24	24	23	23	23	23	24
				24	24	24	24	24	24	24	24	24	25	24	24	24	23	24	23	23	24
				24	23	23	23	23	23	24	24	24	24	24	24	24	23	24	23	23	24
				24	24	24	24	24	24	24	24	24	24	24	24	24	24	24	24	24	24
				24	23	23	23	23	23	24	24	24	24	24	24	24	24	24	24	24	24
				24	24	24	24	24	24	24	24	24	25	24	24	24	24	24	24	24	24
				24	23	24	24	24	24	24	24	24	24	24	24	24	24	24	24	24	24
				24	24	24	24	24	24	24	24	25	24	24	24	24	24	24	24	24	24
				24	23	24	23	24	23	24	24	24	24	24	24	24	24	24	24	24	24
				24	24	24	24	24	24	24	24	24	24	24	24	24	24	24	24	24	24
				24	24	24	23	24	23	24	24	24	24	24	24	24	24	24	24	24	24
				24	24	24	24	24	24	24	24	25	24	24	24	24	24	24	24	24	24
				24	24	24	24	24	24	24	24	24	24	24	24	24	24	24	24	24	24
				24	24	24	24	24	24	24	24	25	25	24	24	24	24	24	24	24	24
				23	23	24	23	23	23	24	23	24	24	24	24	24	24	24	24	24	24
				24	24	24	24	24	24	24	24	25	25	24	24	24	24	24	24	24	24
				0 0 0>;

			PS_Config_Lmt_FW_Diff_P = <
				50	50	50	50	50	50	50	50	50	50	50	50	50	50	50	50	50	50
				50	50	50	50	50	50	50	50	50	50	50	50	50	50	50	50	50	50
				50	50	50	50	50	50	50	50	50	50	50	50	50	50	50	50	50	50
				50	50	50	50	50	50	50	50	50	50	50	50	50	50	50	50	50	50
				50	50	50	50	50	50	50	50	50	50	50	50	50	50	50	50	50	50
				50	50	50	50	50	50	50	50	50	50	50	50	50	50	50	50	50	50
				50	50	50	50	50	50	50	50	50	50	50	50	50	50	50	50	50	50
				50	50	50	50	50	50	50	50	50	50	50	50	50	50	50	50	50	50
				50	50	50	50	50	50	50	50	50	50	50	50	50	50	50	50	50	50
				50	50	50	50	50	50	50	50	50	50	50	50	50	50	50	50	50	50
				50	50	50	50	50	50	50	50	50	50	50	50	50	50	50	50	50	50
				50	50	50	50	50	50	50	50	50	50	50	50	50	50	50	50	50	50
				50	50	50	50	50	50	50	50	50	50	50	50	50	50	50	50	50	50
				50	50	50	50	50	50	50	50	50	50	50	50	50	50	50	50	50	50
				50	50	50	50	50	50	50	50	50	50	50	50	50	50	50	50	50	50
				50	50	50	50	50	50	50	50	50	50	50	50	50	50	50	50	50	50
				50	50	50	50	50	50	50	50	50	50	50	50	50	50	50	50	50	50
				50	50	50	50	50	50	50	50	50	50	50	50	50	50	50	50	50	50
				50	50	50	50	50	50	50	50	50	50	50	50	50	50	50	50	50	50
				50	50	50	50	50	50	50	50	50	50	50	50	50	50	50	50	50	50
				50	50	50	50	50	50	50	50	50	50	50	50	50	50	50	50	50	50
				50	50	50	50	50	50	50	50	50	50	50	50	50	50	50	50	50	50
				50	50	50	50	50	50	50	50	50	50	50	50	50	50	50	50	50	50
				50	50	50	50	50	50	50	50	50	50	50	50	50	50	50	50	50	50
				50	50	50	50	50	50	50	50	50	50	50	50	50	50	50	50	50	50
				50	50	50	50	50	50	50	50	50	50	50	50	50	50	50	50	50	50
				50	50	50	50	50	50	50	50	50	50	50	50	50	50	50	50	50	50
				50	50	50	50	50	50	50	50	50	50	50	50	50	50	50	50	50	50
				50	50	50	50	50	50	50	50	50	50	50	50	50	50	50	50	50	50
				50	50	50	50	50	50	50	50	50	50	50	50	50	50	50	50	50	50
				50	50	50	50	50	50	50	50	50	50	50	50	50	50	50	50	50	50
				50	50	50	50	50	50	50	50	50	50	50	50	50	50	50	50	50	50
				50	50	50	50	50	50	50	50	50	50	50	50	50	50	50	50	50	50
				50	50	50	50	50	50	50	50	50	50	50	50	50	50	50	50	50	50
				50	50	50	50	50	50	50	50	50	50	50	50	50	50	50	50	50	50
				50	50	50	50	50	50	50	50	50	50	50	50	50	50	50	50	50	50
				75 75 75>;

			PS_Config_Lmt_FW_Diff_N = <
				(-50)	(-50)	(-50)	(-50)	(-50)	(-50)	(-50)	(-50)	(-50)	(-50)	(-50)	(-50)	(-50)	(-50)	(-50)	(-50)	(-50)	(-50)
				(-50)	(-50)	(-50)	(-50)	(-50)	(-50)	(-50)	(-50)	(-50)	(-50)	(-50)	(-50)	(-50)	(-50)	(-50)	(-50)	(-50)	(-50)
				(-50)	(-50)	(-50)	(-50)	(-50)	(-50)	(-50)	(-50)	(-50)	(-50)	(-50)	(-50)	(-50)	(-50)	(-50)	(-50)	(-50)	(-50)
				(-50)	(-50)	(-50)	(-50)	(-50)	(-50)	(-50)	(-50)	(-50)	(-50)	(-50)	(-50)	(-50)	(-50)	(-50)	(-50)	(-50)	(-50)
				(-50)	(-50)	(-50)	(-50)	(-50)	(-50)	(-50)	(-50)	(-50)	(-50)	(-50)	(-50)	(-50)	(-50)	(-50)	(-50)	(-50)	(-50)
				(-50)	(-50)	(-50)	(-50)	(-50)	(-50)	(-50)	(-50)	(-50)	(-50)	(-50)	(-50)	(-50)	(-50)	(-50)	(-50)	(-50)	(-50)
				(-50)	(-50)	(-50)	(-50)	(-50)	(-50)	(-50)	(-50)	(-50)	(-50)	(-50)	(-50)	(-50)	(-50)	(-50)	(-50)	(-50)	(-50)
				(-50)	(-50)	(-50)	(-50)	(-50)	(-50)	(-50)	(-50)	(-50)	(-50)	(-50)	(-50)	(-50)	(-50)	(-50)	(-50)	(-50)	(-50)
				(-50)	(-50)	(-50)	(-50)	(-50)	(-50)	(-50)	(-50)	(-50)	(-50)	(-50)	(-50)	(-50)	(-50)	(-50)	(-50)	(-50)	(-50)
				(-50)	(-50)	(-50)	(-50)	(-50)	(-50)	(-50)	(-50)	(-50)	(-50)	(-50)	(-50)	(-50)	(-50)	(-50)	(-50)	(-50)	(-50)
				(-50)	(-50)	(-50)	(-50)	(-50)	(-50)	(-50)	(-50)	(-50)	(-50)	(-50)	(-50)	(-50)	(-50)	(-50)	(-50)	(-50)	(-50)
				(-50)	(-50)	(-50)	(-50)	(-50)	(-50)	(-50)	(-50)	(-50)	(-50)	(-50)	(-50)	(-50)	(-50)	(-50)	(-50)	(-50)	(-50)
				(-50)	(-50)	(-50)	(-50)	(-50)	(-50)	(-50)	(-50)	(-50)	(-50)	(-50)	(-50)	(-50)	(-50)	(-50)	(-50)	(-50)	(-50)
				(-50)	(-50)	(-50)	(-50)	(-50)	(-50)	(-50)	(-50)	(-50)	(-50)	(-50)	(-50)	(-50)	(-50)	(-50)	(-50)	(-50)	(-50)
				(-50)	(-50)	(-50)	(-50)	(-50)	(-50)	(-50)	(-50)	(-50)	(-50)	(-50)	(-50)	(-50)	(-50)	(-50)	(-50)	(-50)	(-50)
				(-50)	(-50)	(-50)	(-50)	(-50)	(-50)	(-50)	(-50)	(-50)	(-50)	(-50)	(-50)	(-50)	(-50)	(-50)	(-50)	(-50)	(-50)
				(-50)	(-50)	(-50)	(-50)	(-50)	(-50)	(-50)	(-50)	(-50)	(-50)	(-50)	(-50)	(-50)	(-50)	(-50)	(-50)	(-50)	(-50)
				(-50)	(-50)	(-50)	(-50)	(-50)	(-50)	(-50)	(-50)	(-50)	(-50)	(-50)	(-50)	(-50)	(-50)	(-50)	(-50)	(-50)	(-50)
				(-50)	(-50)	(-50)	(-50)	(-50)	(-50)	(-50)	(-50)	(-50)	(-50)	(-50)	(-50)	(-50)	(-50)	(-50)	(-50)	(-50)	(-50)
				(-50)	(-50)	(-50)	(-50)	(-50)	(-50)	(-50)	(-50)	(-50)	(-50)	(-50)	(-50)	(-50)	(-50)	(-50)	(-50)	(-50)	(-50)
				(-50)	(-50)	(-50)	(-50)	(-50)	(-50)	(-50)	(-50)	(-50)	(-50)	(-50)	(-50)	(-50)	(-50)	(-50)	(-50)	(-50)	(-50)
				(-50)	(-50)	(-50)	(-50)	(-50)	(-50)	(-50)	(-50)	(-50)	(-50)	(-50)	(-50)	(-50)	(-50)	(-50)	(-50)	(-50)	(-50)
				(-50)	(-50)	(-50)	(-50)	(-50)	(-50)	(-50)	(-50)	(-50)	(-50)	(-50)	(-50)	(-50)	(-50)	(-50)	(-50)	(-50)	(-50)
				(-50)	(-50)	(-50)	(-50)	(-50)	(-50)	(-50)	(-50)	(-50)	(-50)	(-50)	(-50)	(-50)	(-50)	(-50)	(-50)	(-50)	(-50)
				(-50)	(-50)	(-50)	(-50)	(-50)	(-50)	(-50)	(-50)	(-50)	(-50)	(-50)	(-50)	(-50)	(-50)	(-50)	(-50)	(-50)	(-50)
				(-50)	(-50)	(-50)	(-50)	(-50)	(-50)	(-50)	(-50)	(-50)	(-50)	(-50)	(-50)	(-50)	(-50)	(-50)	(-50)	(-50)	(-50)
				(-50)	(-50)	(-50)	(-50)	(-50)	(-50)	(-50)	(-50)	(-50)	(-50)	(-50)	(-50)	(-50)	(-50)	(-50)	(-50)	(-50)	(-50)
				(-50)	(-50)	(-50)	(-50)	(-50)	(-50)	(-50)	(-50)	(-50)	(-50)	(-50)	(-50)	(-50)	(-50)	(-50)	(-50)	(-50)	(-50)
				(-50)	(-50)	(-50)	(-50)	(-50)	(-50)	(-50)	(-50)	(-50)	(-50)	(-50)	(-50)	(-50)	(-50)	(-50)	(-50)	(-50)	(-50)
				(-50)	(-50)	(-50)	(-50)	(-50)	(-50)	(-50)	(-50)	(-50)	(-50)	(-50)	(-50)	(-50)	(-50)	(-50)	(-50)	(-50)	(-50)
				(-50)	(-50)	(-50)	(-50)	(-50)	(-50)	(-50)	(-50)	(-50)	(-50)	(-50)	(-50)	(-50)	(-50)	(-50)	(-50)	(-50)	(-50)
				(-50)	(-50)	(-50)	(-50)	(-50)	(-50)	(-50)	(-50)	(-50)	(-50)	(-50)	(-50)	(-50)	(-50)	(-50)	(-50)	(-50)	(-50)
				(-50)	(-50)	(-50)	(-50)	(-50)	(-50)	(-50)	(-50)	(-50)	(-50)	(-50)	(-50)	(-50)	(-50)	(-50)	(-50)	(-50)	(-50)
				(-50)	(-50)	(-50)	(-50)	(-50)	(-50)	(-50)	(-50)	(-50)	(-50)	(-50)	(-50)	(-50)	(-50)	(-50)	(-50)	(-50)	(-50)
				(-50)	(-50)	(-50)	(-50)	(-50)	(-50)	(-50)	(-50)	(-50)	(-50)	(-50)	(-50)	(-50)	(-50)	(-50)	(-50)	(-50)	(-50)
				(-50)	(-50)	(-50)	(-50)	(-50)	(-50)	(-50)	(-50)	(-50)	(-50)	(-50)	(-50)	(-50)	(-50)	(-50)	(-50)	(-50)	(-50)
				(-75) (-75) (-75)>;

			PS_Config_Lmt_PenTipX_FW_Raw_P = <
				570 570 570 570 570 570 570 570 570 570 570 570 570 570 570 570 570 570 570 570 570 570 570 570 570 570 570 570 570 570 570 570
				570 570 570 570 570 570 570 570 570 570 570 570 570 570 570 570 570 570 570 570 570 570 570 570 570 570 570 570 570 570 570 570
				570 570 570 570 570 570 570 570 570 570 570 570 570 570 570 570 570 570 570 570 570 570 570 570 570 570 570 570 570 570 570 570
				570 570 570 570 570 570 570 570 570 570 570 570 570 570 570 570 570 570 570 570 570 570 570 570 570 570 570 570 570 570 570 570
				570 570 570 570 570 570 570 570 570 570 570 570 570 570 570 570 570 570 570 570 570 570 570 570 570 570 570 570 570 570 570 570
				570 570 570 570 570 570 570 570 570 570 570 570 570 570 570 570 570 570 570 570 570 570 570 570 570 570 570 570 570 570 570 570>;

			PS_Config_Lmt_PenTipX_FW_Raw_N = <
				(-570) (-570) (-570) (-570) (-570) (-570) (-570) (-570) (-570) (-570) (-570) (-570) (-570) (-570) (-570) (-570) (-570) (-570) (-570) (-570) (-570) (-570) (-570) (-570) (-570) (-570) (-570) (-570) (-570) (-570) (-570) (-570)
				(-570) (-570) (-570) (-570) (-570) (-570) (-570) (-570) (-570) (-570) (-570) (-570) (-570) (-570) (-570) (-570) (-570) (-570) (-570) (-570) (-570) (-570) (-570) (-570) (-570) (-570) (-570) (-570) (-570) (-570) (-570) (-570)
				(-570) (-570) (-570) (-570) (-570) (-570) (-570) (-570) (-570) (-570) (-570) (-570) (-570) (-570) (-570) (-570) (-570) (-570) (-570) (-570) (-570) (-570) (-570) (-570) (-570) (-570) (-570) (-570) (-570) (-570) (-570) (-570)
				(-570) (-570) (-570) (-570) (-570) (-570) (-570) (-570) (-570) (-570) (-570) (-570) (-570) (-570) (-570) (-570) (-570) (-570) (-570) (-570) (-570) (-570) (-570) (-570) (-570) (-570) (-570) (-570) (-570) (-570) (-570) (-570)
				(-570) (-570) (-570) (-570) (-570) (-570) (-570) (-570) (-570) (-570) (-570) (-570) (-570) (-570) (-570) (-570) (-570) (-570) (-570) (-570) (-570) (-570) (-570) (-570) (-570) (-570) (-570) (-570) (-570) (-570) (-570) (-570)
				(-570) (-570) (-570) (-570) (-570) (-570) (-570) (-570) (-570) (-570) (-570) (-570) (-570) (-570) (-570) (-570) (-570) (-570) (-570) (-570) (-570) (-570) (-570) (-570) (-570) (-570) (-570) (-570) (-570) (-570) (-570) (-570)>;

			PS_Config_Lmt_PenTipY_FW_Raw_P = <
				570 570 570 570
				570 570 570 570
				570 570 570 570
				570 570 570 570
				570 570 570 570
				570 570 570 570
				570 570 570 570
				570 570 570 570
				570 570 570 570
				570 570 570 570
				570 570 570 570
				570 570 570 570
				570 570 570 570
				570 570 570 570
				570 570 570 570
				570 570 570 570
				570 570 570 570
				570 570 570 570
				570 570 570 570
				570 570 570 570
				570 570 570 570
				570 570 570 570
				570 570 570 570
				570 570 570 570
				570 570 570 570
				570 570 570 570
				570 570 570 570
				570 570 570 570
				570 570 570 570
				570 570 570 570
				570 570 570 570
				570 570 570 570
				570 570 570 570
				570 570 570 570
				570 570 570 570
				570 570 570 570
				570 570 570 570
				570 570 570 570
				570 570 570 570
				570 570 570 570
				570 570 570 570
				570 570 570 570
				570 570 570 570
				570 570 570 570
				570 570 570 570
				570 570 570 570
				570 570 570 570
				570 570 570 570
				570 570 570 570
				570 570 570 570>;

			PS_Config_Lmt_PenTipY_FW_Raw_N = <
				(-570) (-570) (-570) (-570)
				(-570) (-570) (-570) (-570)
				(-570) (-570) (-570) (-570)
				(-570) (-570) (-570) (-570)
				(-570) (-570) (-570) (-570)
				(-570) (-570) (-570) (-570)
				(-570) (-570) (-570) (-570)
				(-570) (-570) (-570) (-570)
				(-570) (-570) (-570) (-570)
				(-570) (-570) (-570) (-570)
				(-570) (-570) (-570) (-570)
				(-570) (-570) (-570) (-570)
				(-570) (-570) (-570) (-570)
				(-570) (-570) (-570) (-570)
				(-570) (-570) (-570) (-570)
				(-570) (-570) (-570) (-570)
				(-570) (-570) (-570) (-570)
				(-570) (-570) (-570) (-570)
				(-570) (-570) (-570) (-570)
				(-570) (-570) (-570) (-570)
				(-570) (-570) (-570) (-570)
				(-570) (-570) (-570) (-570)
				(-570) (-570) (-570) (-570)
				(-570) (-570) (-570) (-570)
				(-570) (-570) (-570) (-570)
				(-570) (-570) (-570) (-570)
				(-570) (-570) (-570) (-570)
				(-570) (-570) (-570) (-570)
				(-570) (-570) (-570) (-570)
				(-570) (-570) (-570) (-570)
				(-570) (-570) (-570) (-570)
				(-570) (-570) (-570) (-570)
				(-570) (-570) (-570) (-570)
				(-570) (-570) (-570) (-570)
				(-570) (-570) (-570) (-570)
				(-570) (-570) (-570) (-570)
				(-570) (-570) (-570) (-570)
				(-570) (-570) (-570) (-570)
				(-570) (-570) (-570) (-570)
				(-570) (-570) (-570) (-570)
				(-570) (-570) (-570) (-570)
				(-570) (-570) (-570) (-570)
				(-570) (-570) (-570) (-570)
				(-570) (-570) (-570) (-570)
				(-570) (-570) (-570) (-570)
				(-570) (-570) (-570) (-570)
				(-570) (-570) (-570) (-570)
				(-570) (-570) (-570) (-570)
				(-570) (-570) (-570) (-570)
				(-570) (-570) (-570) (-570)>;

			PS_Config_Lmt_PenRingX_FW_Raw_P = <
				570 570 570 570 570 570 570 570 570 570 570 570 570 570 570 570 570 570 570 570 570 570 570 570 570 570 570 570 570 570 570 570
				570 570 570 570 570 570 570 570 570 570 570 570 570 570 570 570 570 570 570 570 570 570 570 570 570 570 570 570 570 570 570 570
				570 570 570 570 570 570 570 570 570 570 570 570 570 570 570 570 570 570 570 570 570 570 570 570 570 570 570 570 570 570 570 570
				570 570 570 570 570 570 570 570 570 570 570 570 570 570 570 570 570 570 570 570 570 570 570 570 570 570 570 570 570 570 570 570
				570 570 570 570 570 570 570 570 570 570 570 570 570 570 570 570 570 570 570 570 570 570 570 570 570 570 570 570 570 570 570 570
				570 570 570 570 570 570 570 570 570 570 570 570 570 570 570 570 570 570 570 570 570 570 570 570 570 570 570 570 570 570 570 570>;

			PS_Config_Lmt_PenRingX_FW_Raw_N = <
				(-570) (-570) (-570) (-570) (-570) (-570) (-570) (-570) (-570) (-570) (-570) (-570) (-570) (-570) (-570) (-570) (-570) (-570) (-570) (-570) (-570) (-570) (-570) (-570) (-570) (-570) (-570) (-570) (-570) (-570) (-570) (-570)
				(-570) (-570) (-570) (-570) (-570) (-570) (-570) (-570) (-570) (-570) (-570) (-570) (-570) (-570) (-570) (-570) (-570) (-570) (-570) (-570) (-570) (-570) (-570) (-570) (-570) (-570) (-570) (-570) (-570) (-570) (-570) (-570)
				(-570) (-570) (-570) (-570) (-570) (-570) (-570) (-570) (-570) (-570) (-570) (-570) (-570) (-570) (-570) (-570) (-570) (-570) (-570) (-570) (-570) (-570) (-570) (-570) (-570) (-570) (-570) (-570) (-570) (-570) (-570) (-570)
				(-570) (-570) (-570) (-570) (-570) (-570) (-570) (-570) (-570) (-570) (-570) (-570) (-570) (-570) (-570) (-570) (-570) (-570) (-570) (-570) (-570) (-570) (-570) (-570) (-570) (-570) (-570) (-570) (-570) (-570) (-570) (-570)
				(-570) (-570) (-570) (-570) (-570) (-570) (-570) (-570) (-570) (-570) (-570) (-570) (-570) (-570) (-570) (-570) (-570) (-570) (-570) (-570) (-570) (-570) (-570) (-570) (-570) (-570) (-570) (-570) (-570) (-570) (-570) (-570)
				(-570) (-570) (-570) (-570) (-570) (-570) (-570) (-570) (-570) (-570) (-570) (-570) (-570) (-570) (-570) (-570) (-570) (-570) (-570) (-570) (-570) (-570) (-570) (-570) (-570) (-570) (-570) (-570) (-570) (-570) (-570) (-570)>;

			PS_Config_Lmt_PenRingY_FW_Raw_P = <
				570 570 570 570
				570 570 570 570
				570 570 570 570
				570 570 570 570
				570 570 570 570
				570 570 570 570
				570 570 570 570
				570 570 570 570
				570 570 570 570
				570 570 570 570
				570 570 570 570
				570 570 570 570
				570 570 570 570
				570 570 570 570
				570 570 570 570
				570 570 570 570
				570 570 570 570
				570 570 570 570
				570 570 570 570
				570 570 570 570
				570 570 570 570
				570 570 570 570
				570 570 570 570
				570 570 570 570
				570 570 570 570
				570 570 570 570
				570 570 570 570
				570 570 570 570
				570 570 570 570
				570 570 570 570
				570 570 570 570
				570 570 570 570
				570 570 570 570
				570 570 570 570
				570 570 570 570
				570 570 570 570
				570 570 570 570
				570 570 570 570
				570 570 570 570
				570 570 570 570
				570 570 570 570
				570 570 570 570
				570 570 570 570
				570 570 570 570
				570 570 570 570
				570 570 570 570
				570 570 570 570
				570 570 570 570
				570 570 570 570
				570 570 570 570>;

			PS_Config_Lmt_PenRingY_FW_Raw_N = <
				(-570) (-570) (-570) (-570)
				(-570) (-570) (-570) (-570)
				(-570) (-570) (-570) (-570)
				(-570) (-570) (-570) (-570)
				(-570) (-570) (-570) (-570)
				(-570) (-570) (-570) (-570)
				(-570) (-570) (-570) (-570)
				(-570) (-570) (-570) (-570)
				(-570) (-570) (-570) (-570)
				(-570) (-570) (-570) (-570)
				(-570) (-570) (-570) (-570)
				(-570) (-570) (-570) (-570)
				(-570) (-570) (-570) (-570)
				(-570) (-570) (-570) (-570)
				(-570) (-570) (-570) (-570)
				(-570) (-570) (-570) (-570)
				(-570) (-570) (-570) (-570)
				(-570) (-570) (-570) (-570)
				(-570) (-570) (-570) (-570)
				(-570) (-570) (-570) (-570)
				(-570) (-570) (-570) (-570)
				(-570) (-570) (-570) (-570)
				(-570) (-570) (-570) (-570)
				(-570) (-570) (-570) (-570)
				(-570) (-570) (-570) (-570)
				(-570) (-570) (-570) (-570)
				(-570) (-570) (-570) (-570)
				(-570) (-570) (-570) (-570)
				(-570) (-570) (-570) (-570)
				(-570) (-570) (-570) (-570)
				(-570) (-570) (-570) (-570)
				(-570) (-570) (-570) (-570)
				(-570) (-570) (-570) (-570)
				(-570) (-570) (-570) (-570)
				(-570) (-570) (-570) (-570)
				(-570) (-570) (-570) (-570)
				(-570) (-570) (-570) (-570)
				(-570) (-570) (-570) (-570)
				(-570) (-570) (-570) (-570)
				(-570) (-570) (-570) (-570)
				(-570) (-570) (-570) (-570)
				(-570) (-570) (-570) (-570)
				(-570) (-570) (-570) (-570)
				(-570) (-570) (-570) (-570)
				(-570) (-570) (-570) (-570)
				(-570) (-570) (-570) (-570)
				(-570) (-570) (-570) (-570)
				(-570) (-570) (-570) (-570)
				(-570) (-570) (-570) (-570)
				(-570) (-570) (-570) (-570)>;

			PS_Config_Lmt_PenTipX_FW_Diff_P = <
				870 870 870 870 870 870 870 870 870 870 870 870 870 870 870 870 870 870 870 870 870 870 870 870 870 870 870 870 870 870 870 870
				870 870 870 870 870 870 870 870 870 870 870 870 870 870 870 870 870 870 870 870 870 870 870 870 870 870 870 870 870 870 870 870
				870 870 870 870 870 870 870 870 870 870 870 870 870 870 870 870 870 870 870 870 870 870 870 870 870 870 870 870 870 870 870 870
				870 870 870 870 870 870 870 870 870 870 870 870 870 870 870 870 870 870 870 870 870 870 870 870 870 870 870 870 870 870 870 870
				870 870 870 870 870 870 870 870 870 870 870 870 870 870 870 870 870 870 870 870 870 870 870 870 870 870 870 870 870 870 870 870
				870 870 870 870 870 870 870 870 870 870 870 870 870 870 870 870 870 870 870 870 870 870 870 870 870 870 870 870 870 870 870 870>;

			PS_Config_Lmt_PenTipX_FW_Diff_N = <
				(-870) (-870) (-870) (-870) (-870) (-870) (-870) (-870) (-870) (-870) (-870) (-870) (-870) (-870) (-870) (-870) (-870) (-870) (-870) (-870) (-870) (-870) (-870) (-870) (-870) (-870) (-870) (-870) (-870) (-870) (-870) (-870)
				(-870) (-870) (-870) (-870) (-870) (-870) (-870) (-870) (-870) (-870) (-870) (-870) (-870) (-870) (-870) (-870) (-870) (-870) (-870) (-870) (-870) (-870) (-870) (-870) (-870) (-870) (-870) (-870) (-870) (-870) (-870) (-870)
				(-870) (-870) (-870) (-870) (-870) (-870) (-870) (-870) (-870) (-870) (-870) (-870) (-870) (-870) (-870) (-870) (-870) (-870) (-870) (-870) (-870) (-870) (-870) (-870) (-870) (-870) (-870) (-870) (-870) (-870) (-870) (-870)
				(-870) (-870) (-870) (-870) (-870) (-870) (-870) (-870) (-870) (-870) (-870) (-870) (-870) (-870) (-870) (-870) (-870) (-870) (-870) (-870) (-870) (-870) (-870) (-870) (-870) (-870) (-870) (-870) (-870) (-870) (-870) (-870)
				(-870) (-870) (-870) (-870) (-870) (-870) (-870) (-870) (-870) (-870) (-870) (-870) (-870) (-870) (-870) (-870) (-870) (-870) (-870) (-870) (-870) (-870) (-870) (-870) (-870) (-870) (-870) (-870) (-870) (-870) (-870) (-870)
				(-870) (-870) (-870) (-870) (-870) (-870) (-870) (-870) (-870) (-870) (-870) (-870) (-870) (-870) (-870) (-870) (-870) (-870) (-870) (-870) (-870) (-870) (-870) (-870) (-870) (-870) (-870) (-870) (-870) (-870) (-870) (-870)>;

			PS_Config_Lmt_PenTipY_FW_Diff_P = <
				870 870 870 870
				870 870 870 870
				870 870 870 870
				870 870 870 870
				870 870 870 870
				870 870 870 870
				870 870 870 870
				870 870 870 870
				870 870 870 870
				870 870 870 870
				870 870 870 870
				870 870 870 870
				870 870 870 870
				870 870 870 870
				870 870 870 870
				870 870 870 870
				870 870 870 870
				870 870 870 870
				870 870 870 870
				870 870 870 870
				870 870 870 870
				870 870 870 870
				870 870 870 870
				870 870 870 870
				870 870 870 870
				870 870 870 870
				870 870 870 870
				870 870 870 870
				870 870 870 870
				870 870 870 870
				870 870 870 870
				870 870 870 870
				870 870 870 870
				870 870 870 870
				870 870 870 870
				870 870 870 870
				870 870 870 870
				870 870 870 870
				870 870 870 870
				870 870 870 870
				870 870 870 870
				870 870 870 870
				870 870 870 870
				870 870 870 870
				870 870 870 870
				870 870 870 870
				870 870 870 870
				870 870 870 870
				870 870 870 870
				870 870 870 870>;

			PS_Config_Lmt_PenTipY_FW_Diff_N = <
				(-870) (-870) (-870) (-870)
				(-870) (-870) (-870) (-870)
				(-870) (-870) (-870) (-870)
				(-870) (-870) (-870) (-870)
				(-870) (-870) (-870) (-870)
				(-870) (-870) (-870) (-870)
				(-870) (-870) (-870) (-870)
				(-870) (-870) (-870) (-870)
				(-870) (-870) (-870) (-870)
				(-870) (-870) (-870) (-870)
				(-870) (-870) (-870) (-870)
				(-870) (-870) (-870) (-870)
				(-870) (-870) (-870) (-870)
				(-870) (-870) (-870) (-870)
				(-870) (-870) (-870) (-870)
				(-870) (-870) (-870) (-870)
				(-870) (-870) (-870) (-870)
				(-870) (-870) (-870) (-870)
				(-870) (-870) (-870) (-870)
				(-870) (-870) (-870) (-870)
				(-870) (-870) (-870) (-870)
				(-870) (-870) (-870) (-870)
				(-870) (-870) (-870) (-870)
				(-870) (-870) (-870) (-870)
				(-870) (-870) (-870) (-870)
				(-870) (-870) (-870) (-870)
				(-870) (-870) (-870) (-870)
				(-870) (-870) (-870) (-870)
				(-870) (-870) (-870) (-870)
				(-870) (-870) (-870) (-870)
				(-870) (-870) (-870) (-870)
				(-870) (-870) (-870) (-870)
				(-870) (-870) (-870) (-870)
				(-870) (-870) (-870) (-870)
				(-870) (-870) (-870) (-870)
				(-870) (-870) (-870) (-870)
				(-870) (-870) (-870) (-870)
				(-870) (-870) (-870) (-870)
				(-870) (-870) (-870) (-870)
				(-870) (-870) (-870) (-870)
				(-870) (-870) (-870) (-870)
				(-870) (-870) (-870) (-870)
				(-870) (-870) (-870) (-870)
				(-870) (-870) (-870) (-870)
				(-870) (-870) (-870) (-870)
				(-870) (-870) (-870) (-870)
				(-870) (-870) (-870) (-870)
				(-870) (-870) (-870) (-870)
				(-870) (-870) (-870) (-870)
				(-870) (-870) (-870) (-870)>;

			PS_Config_Lmt_PenRingX_FW_Diff_P = <
				870 870 870 870 870 870 870 870 870 870 870 870 870 870 870 870 870 870 870 870 870 870 870 870 870 870 870 870 870 870 870 870
				870 870 870 870 870 870 870 870 870 870 870 870 870 870 870 870 870 870 870 870 870 870 870 870 870 870 870 870 870 870 870 870
				870 870 870 870 870 870 870 870 870 870 870 870 870 870 870 870 870 870 870 870 870 870 870 870 870 870 870 870 870 870 870 870
				870 870 870 870 870 870 870 870 870 870 870 870 870 870 870 870 870 870 870 870 870 870 870 870 870 870 870 870 870 870 870 870
				870 870 870 870 870 870 870 870 870 870 870 870 870 870 870 870 870 870 870 870 870 870 870 870 870 870 870 870 870 870 870 870
				870 870 870 870 870 870 870 870 870 870 870 870 870 870 870 870 870 870 870 870 870 870 870 870 870 870 870 870 870 870 870 870>;

			PS_Config_Lmt_PenRingX_FW_Diff_N = <
				(-870) (-870) (-870) (-870) (-870) (-870) (-870) (-870) (-870) (-870) (-870) (-870) (-870) (-870) (-870) (-870) (-870) (-870) (-870) (-870) (-870) (-870) (-870) (-870) (-870) (-870) (-870) (-870) (-870) (-870) (-870) (-870)
				(-870) (-870) (-870) (-870) (-870) (-870) (-870) (-870) (-870) (-870) (-870) (-870) (-870) (-870) (-870) (-870) (-870) (-870) (-870) (-870) (-870) (-870) (-870) (-870) (-870) (-870) (-870) (-870) (-870) (-870) (-870) (-870)
				(-870) (-870) (-870) (-870) (-870) (-870) (-870) (-870) (-870) (-870) (-870) (-870) (-870) (-870) (-870) (-870) (-870) (-870) (-870) (-870) (-870) (-870) (-870) (-870) (-870) (-870) (-870) (-870) (-870) (-870) (-870) (-870)
				(-870) (-870) (-870) (-870) (-870) (-870) (-870) (-870) (-870) (-870) (-870) (-870) (-870) (-870) (-870) (-870) (-870) (-870) (-870) (-870) (-870) (-870) (-870) (-870) (-870) (-870) (-870) (-870) (-870) (-870) (-870) (-870)
				(-870) (-870) (-870) (-870) (-870) (-870) (-870) (-870) (-870) (-870) (-870) (-870) (-870) (-870) (-870) (-870) (-870) (-870) (-870) (-870) (-870) (-870) (-870) (-870) (-870) (-870) (-870) (-870) (-870) (-870) (-870) (-870)
				(-870) (-870) (-870) (-870) (-870) (-870) (-870) (-870) (-870) (-870) (-870) (-870) (-870) (-870) (-870) (-870) (-870) (-870) (-870) (-870) (-870) (-870) (-870) (-870) (-870) (-870) (-870) (-870) (-870) (-870) (-870) (-870)>;

			PS_Config_Lmt_PenRingY_FW_Diff_P = <
				870 870 870 870
				870 870 870 870
				870 870 870 870
				870 870 870 870
				870 870 870 870
				870 870 870 870
				870 870 870 870
				870 870 870 870
				870 870 870 870
				870 870 870 870
				870 870 870 870
				870 870 870 870
				870 870 870 870
				870 870 870 870
				870 870 870 870
				870 870 870 870
				870 870 870 870
				870 870 870 870
				870 870 870 870
				870 870 870 870
				870 870 870 870
				870 870 870 870
				870 870 870 870
				870 870 870 870
				870 870 870 870
				870 870 870 870
				870 870 870 870
				870 870 870 870
				870 870 870 870
				870 870 870 870
				870 870 870 870
				870 870 870 870
				870 870 870 870
				870 870 870 870
				870 870 870 870
				870 870 870 870
				870 870 870 870
				870 870 870 870
				870 870 870 870
				870 870 870 870
				870 870 870 870
				870 870 870 870
				870 870 870 870
				870 870 870 870
				870 870 870 870
				870 870 870 870
				870 870 870 870
				870 870 870 870
				870 870 870 870
				870 870 870 870>;

			PS_Config_Lmt_PenRingY_FW_Diff_N = <
				(-870) (-870) (-870) (-870)
				(-870) (-870) (-870) (-870)
				(-870) (-870) (-870) (-870)
				(-870) (-870) (-870) (-870)
				(-870) (-870) (-870) (-870)
				(-870) (-870) (-870) (-870)
				(-870) (-870) (-870) (-870)
				(-870) (-870) (-870) (-870)
				(-870) (-870) (-870) (-870)
				(-870) (-870) (-870) (-870)
				(-870) (-870) (-870) (-870)
				(-870) (-870) (-870) (-870)
				(-870) (-870) (-870) (-870)
				(-870) (-870) (-870) (-870)
				(-870) (-870) (-870) (-870)
				(-870) (-870) (-870) (-870)
				(-870) (-870) (-870) (-870)
				(-870) (-870) (-870) (-870)
				(-870) (-870) (-870) (-870)
				(-870) (-870) (-870) (-870)
				(-870) (-870) (-870) (-870)
				(-870) (-870) (-870) (-870)
				(-870) (-870) (-870) (-870)
				(-870) (-870) (-870) (-870)
				(-870) (-870) (-870) (-870)
				(-870) (-870) (-870) (-870)
				(-870) (-870) (-870) (-870)
				(-870) (-870) (-870) (-870)
				(-870) (-870) (-870) (-870)
				(-870) (-870) (-870) (-870)
				(-870) (-870) (-870) (-870)
				(-870) (-870) (-870) (-870)
				(-870) (-870) (-870) (-870)
				(-870) (-870) (-870) (-870)
				(-870) (-870) (-870) (-870)
				(-870) (-870) (-870) (-870)
				(-870) (-870) (-870) (-870)
				(-870) (-870) (-870) (-870)
				(-870) (-870) (-870) (-870)
				(-870) (-870) (-870) (-870)
				(-870) (-870) (-870) (-870)
				(-870) (-870) (-870) (-870)
				(-870) (-870) (-870) (-870)
				(-870) (-870) (-870) (-870)
				(-870) (-870) (-870) (-870)
				(-870) (-870) (-870) (-870)
				(-870) (-870) (-870) (-870)
				(-870) (-870) (-870) (-870)
				(-870) (-870) (-870) (-870)
				(-870) (-870) (-870) (-870)>;

			PS_Config_Diff_Test_Frame = <50>;
		};

		/*for Xiaomi K19A 672C JDI6.497" Truly Module*/
		novatek-mp-criteria-5956@0 {
			#address-cells = <1>;
			#size-cells = <0>;
			compatible = "novatek-mp-criteria-5956";

			/* MP Config */
			IC_X_CFG_SIZE = <16>;
			IC_Y_CFG_SIZE = <36>;
			IC_KEY_CFG_SIZE = <4>;
			X_Channel = <16>;
			Y_Channel = <36>;
			AIN_X = <0 1 2 3 4 5 6 7 8 9 10 11 12 13 14 15>;
			AIN_Y = <0 1 2 3 4 5 6 7 8 9 10 11 12 13 14 15 16 17 18 19 20 21 22 23 24 25 26 27 28 29 30 31 32 33 34 35>;
			//AIN_X = <0 1 2 3 4 5 6 7 8 9 10 11 12 13 14 15 16 17 18 19 20 21 22 23 24 25 26 27 28 29 30 31>;
			//AIN_Y = <0 1 2 3 4 5 6 7 8 9 10 11 12 13 14 15 16 17 18 19 20 21 22 23 24 25 26 27 28 29 30 31 32 33 34 35 36 37 38 39 40 41 42 43 44 45 46 47 48 49>;
			AIN_KEY = <0 1 2 0xFF>;

			/* MP Criteria */
			PS_Config_Lmt_Short_Rawdata_P = <
				14008 14008 14008 14008 14008 14008 14008 14008 14008 14008 14008 14008 14008 14008 14008 14008
				14008 14008 14008 14008 14008 14008 14008 14008 14008 14008 14008 14008 14008 14008 14008 14008
				14008 14008 14008 14008 14008 14008 14008 14008 14008 14008 14008 14008 14008 14008 14008 14008
				14008 14008 14008 14008 14008 14008 14008 14008 14008 14008 14008 14008 14008 14008 14008 14008
				14008 14008 14008 14008 14008 14008 14008 14008 14008 14008 14008 14008 14008 14008 14008 14008
				14008 14008 14008 14008 14008 14008 14008 14008 14008 14008 14008 14008 14008 14008 14008 14008
				14008 14008 14008 14008 14008 14008 14008 14008 14008 14008 14008 14008 14008 14008 14008 14008
				14008 14008 14008 14008 14008 14008 14008 14008 14008 14008 14008 14008 14008 14008 14008 14008
				14008 14008 14008 14008 14008 14008 14008 14008 14008 14008 14008 14008 14008 14008 14008 14008
				14008 14008 14008 14008 14008 14008 14008 14008 14008 14008 14008 14008 14008 14008 14008 14008
				14008 14008 14008 14008 14008 14008 14008 14008 14008 14008 14008 14008 14008 14008 14008 14008
				14008 14008 14008 14008 14008 14008 14008 14008 14008 14008 14008 14008 14008 14008 14008 14008
				14008 14008 14008 14008 14008 14008 14008 14008 14008 14008 14008 14008 14008 14008 14008 14008
				14008 14008 14008 14008 14008 14008 14008 14008 14008 14008 14008 14008 14008 14008 14008 14008
				14008 14008 14008 14008 14008 14008 14008 14008 14008 14008 14008 14008 14008 14008 14008 14008
				14008 14008 14008 14008 14008 14008 14008 14008 14008 14008 14008 14008 14008 14008 14008 14008
				14008 14008 14008 14008 14008 14008 14008 14008 14008 14008 14008 14008 14008 14008 14008 14008
				14008 14008 14008 14008 14008 14008 14008 14008 14008 14008 14008 14008 14008 14008 14008 14008
				14008 14008 14008 14008 14008 14008 14008 14008 14008 14008 14008 14008 14008 14008 14008 14008
				14008 14008 14008 14008 14008 14008 14008 14008 14008 14008 14008 14008 14008 14008 14008 14008
				14008 14008 14008 14008 14008 14008 14008 14008 14008 14008 14008 14008 14008 14008 14008 14008
				14008 14008 14008 14008 14008 14008 14008 14008 14008 14008 14008 14008 14008 14008 14008 14008
				14008 14008 14008 14008 14008 14008 14008 14008 14008 14008 14008 14008 14008 14008 14008 14008
				14008 14008 14008 14008 14008 14008 14008 14008 14008 14008 14008 14008 14008 14008 14008 14008
				14008 14008 14008 14008 14008 14008 14008 14008 14008 14008 14008 14008 14008 14008 14008 14008
				14008 14008 14008 14008 14008 14008 14008 14008 14008 14008 14008 14008 14008 14008 14008 14008
				14008 14008 14008 14008 14008 14008 14008 14008 14008 14008 14008 14008 14008 14008 14008 14008
				14008 14008 14008 14008 14008 14008 14008 14008 14008 14008 14008 14008 14008 14008 14008 14008
				14008 14008 14008 14008 14008 14008 14008 14008 14008 14008 14008 14008 14008 14008 14008 14008
				14008 14008 14008 14008 14008 14008 14008 14008 14008 14008 14008 14008 14008 14008 14008 14008
				14008 14008 14008 14008 14008 14008 14008 14008 14008 14008 14008 14008 14008 14008 14008 14008
				14008 14008 14008 14008 14008 14008 14008 14008 14008 14008 14008 14008 14008 14008 14008 14008
				14008 14008 14008 14008 14008 14008 14008 14008 14008 14008 14008 14008 14008 14008 14008 14008
				14008 14008 14008 14008 14008 14008 14008 14008 14008 14008 14008 14008 14008 14008 14008 14008
				14008 14008 14008 14008 14008 14008 14008 14008 14008 14008 14008 14008 14008 14008 14008 14008
				14008 14008 14008 14008 14008 14008 14008 14008 14008 14008 14008 14008 14008 14008 14008 14008
				14008 14008 14008>;

			PS_Config_Lmt_Short_Rawdata_N = <
				10100	10100	10100	10100	10100	10100	10100	10100	10100	10100	10100	10100	10100	10100	10100	10100
				10100	10100	10100	10100	10100	10100	10100	10100	10100	10100	10100	10100	10100	10100	10100	10100
				10100	10100	10100	10100	10100	10100	10100	10100	10100	10100	10100	10100	10100	10100	10100	10100
				10100	10100	10100	10100	10100	10100	10100	10100	10100	10100	10100	10100	10100	10100	10100	10100
				10100	10100	10100	10100	10100	10100	10100	10100	10100	10100	10100	10100	10100	10100	10100	10100
				10100	10100	10100	10100	10100	10100	10100	10100	10100	10100	10100	10100	10100	10100	10100	10100
				10100	10100	10100	10100	10100	10100	10100	10100	10100	10100	10100	10100	10100	10100	10100	10100
				10100	10100	10100	10100	10100	10100	10100	10100	10100	10100	10100	10100	10100	10100	10100	10100
				10100	10100	10100	10100	10100	10100	10100	10100	10100	10100	10100	10100	10100	10100	10100	10100
				10100	10100	10100	10100	10100	10100	10100	10100	10100	10100	10100	10100	10100	10100	10100	10100
				10100	10100	10100	10100	10100	10100	10100	10100	10100	10100	10100	10100	10100	10100	10100	10100
				10100	10100	10100	10100	10100	10100	10100	10100	10100	10100	10100	10100	10100	10100	10100	10100
				10100	10100	10100	10100	10100	10100	10100	10100	10100	10100	10100	10100	10100	10100	10100	10100
				10100	10100	10100	10100	10100	10100	10100	10100	10100	10100	10100	10100	10100	10100	10100	10100
				10100	10100	10100	10100	10100	10100	10100	10100	10100	10100	10100	10100	10100	10100	10100	10100
				10100	10100	10100	10100	10100	10100	10100	10100	10100	10100	10100	10100	10100	10100	10100	10100
				10100	10100	10100	10100	10100	10100	10100	10100	10100	10100	10100	10100	10100	10100	10100	10100
				10100	10100	10100	10100	10100	10100	10100	10100	10100	10100	10100	10100	10100	10100	10100	10100
				10100	10100	10100	10100	10100	10100	10100	10100	10100	10100	10100	10100	10100	10100	10100	10100
				10100	10100	10100	10100	10100	10100	10100	10100	10100	10100	10100	10100	10100	10100	10100	10100
				10100	10100	10100	10100	10100	10100	10100	10100	10100	10100	10100	10100	10100	10100	10100	10100
				10100	10100	10100	10100	10100	10100	10100	10100	10100	10100	10100	10100	10100	10100	10100	10100
				10100	10100	10100	10100	10100	10100	10100	10100	10100	10100	10100	10100	10100	10100	10100	10100
				10100	10100	10100	10100	10100	10100	10100	10100	10100	10100	10100	10100	10100	10100	10100	10100
				10100	10100	10100	10100	10100	10100	10100	10100	10100	10100	10100	10100	10100	10100	10100	10100
				10100	10100	10100	10100	10100	10100	10100	10100	10100	10100	10100	10100	10100	10100	10100	10100
				10100	10100	10100	10100	10100	10100	10100	10100	10100	10100	10100	10100	10100	10100	10100	10100
				10100	10100	10100	10100	10100	10100	10100	10100	10100	10100	10100	10100	10100	10100	10100	10100
				10100	10100	10100	10100	10100	10100	10100	10100	10100	10100	10100	10100	10100	10100	10100	10100
				10100	10100	10100	10100	10100	10100	10100	10100	10100	10100	10100	10100	10100	10100	10100	10100
				10100	10100	10100	10100	10100	10100	10100	10100	10100	10100	10100	10100	10100	10100	10100	10100
				10100	10100	10100	10100	10100	10100	10100	10100	10100	10100	10100	10100	10100	10100	10100	10100
				10100	10100	10100	10100	10100	10100	10100	10100	10100	10100	10100	10100	10100	10100	10100	10100
				10100	10100	10100	10100	10100	10100	10100	10100	10100	10100	10100	10100	10100	10100	10100	10100
				10100	10100	10100	10100	10100	10100	10100	10100	10100	10100	10100	10100	10100	10100	10100	10100
				10100	10100	10100	10100	10100	10100	10100	10100	10100	10100	10100	10100	10100	10100	10100	10100
				10000 10000 10000>;

			PS_Config_Lmt_Open_Rawdata_P = <
				3563	3970	3922	3869	3841	3834	3850	3764	3918	4037	4020	4027	3962	3959	3945	3526
				3771	3990	3914	3861	3837	3827	3840	3795	3976	4050	4026	4041	3977	3974	3984	3736
				3935	3943	3868	3803	3788	3774	3791	3784	3971	3973	3957	3967	3911	3918	3953	3890
				3924	3934	3857	3782	3763	3750	3771	3731	3938	3949	3931	3943	3901	3906	3952	3859
				3883	3904	3816	3747	3739	3721	3738	3725	3830	3847	3837	3847	3802	3830	3866	3816
				3851	3875	3777	3718	3698	3680	3694	3680	3817	3837	3829	3833	3801	3834	3872	3820
				3820	3854	3760	3690	3675	3661	3670	3656	3792	3816	3801	3815	3785	3816	3861	3815
				3796	3838	3739	3662	3649	3640	3624	3637	3780	3805	3787	3801	3770	3801	3820	3803
				3788	3826	3732	3655	3645	3630	3651	3633	3725	3740	3728	3735	3719	3752	3808	3759
				3754	3792	3700	3620	3610	3596	3616	3595	3708	3725	3712	3719	3710	3739	3803	3752
				3756	3805	3701	3630	3614	3577	3621	3600	3654	3680	3668	3670	3670	3679	3767	3722
				3698	3739	3634	3568	3553	3539	3561	3537	3617	3644	3630	3634	3640	3679	3742	3701
				3672	3715	3621	3547	3530	3523	3540	3518	3589	3616	3598	3606	3617	3647	3721	3680
				3642	3690	3598	3519	3502	3500	3509	3487	3551	3577	3560	3567	3581	3614	3687	3647
				3628	3669	3582	3501	3465	3480	3497	3472	3497	3518	3505	3511	3505	3570	3644	3603
				3582	3617	3535	3456	3439	3432	3448	3423	3469	3490	3480	3483	3504	3544	3627	3582
				3549	3588	3504	3427	3413	3406	3416	3395	3416	3441	3427	3430	3446	3502	3579	3542
				3530	3570	3477	3383	3389	3379	3393	3375	3367	3395	3382	3367	3403	3465	3544	3509
				3477	3515	3434	3375	3361	3358	3367	3343	3325	3350	3336	3340	3360	3441	3530	3500
				3458	3498	3418	3358	3344	3341	3347	3330	3263	3287	3276	3285	3299	3382	3474	3445
				3397	3428	3347	3295	3285	3276	3281	3263	3232	3248	3243	3249	3264	3347	3448	3417
				3404	3431	3332	3298	3285	3277	3281	3263	3166	3183	3164	3186	3204	3285	3395	3362
				3357	3385	3297	3245	3235	3225	3228	3210	3126	3144	3143	3147	3165	3249	3358	3333
				3311	3339	3249	3197	3192	3185	3185	3171	3066	3084	3087	3089	3105	3193	3299	3277
				3269	3291	3208	3154	3148	3144	3141	3126	3040	3057	3057	3061	3081	3165	3280	3259
				3211	3215	3151	3091	3091	3087	3084	3068	2991	2991	3008	3015	3031	3115	3232	3213
				3161	3176	3091	3032	3035	3031	3031	3014	2938	2955	2958	2961	2977	3063	3183	3168
				3147	3165	3075	3018	3022	3015	3014	2997	2888	2903	2909	2910	2928	3011	3136	3124
				3067	3102	3010	2954	2958	2954	2951	2940	2818	2846	2847	2853	2868	2955	3073	3068
				3033	3054	2958	2902	2909	2903	2899	2888	2779	2797	2800	2804	2819	2906	3025	3026
				3004	3021	2928	2867	2879	2875	2868	2853	2744	2759	2762	2767	2783	2865	2986	2989
				2942	2959	2865	2801	2816	2812	2807	2790	2695	2711	2713	2720	2737	2819	2942	2945
				2942	2959	2861	2797	2814	2809	2809	2790	2660	2676	2682	2683	2700	2788	2914	2921
				2903	2920	2821	2756	2773	2769	2770	2755	2616	2630	2634	2634	2651	2741	2868	2875
				2658	2912	2805	2742	2760	2762	2760	2744	2620	2639	2637	2639	2655	2746	2878	2657
				2767	2832	2723	2660	2679	2679	2682	2667	2541	2563	2555	2556	2573	2667	2800	2772
				5120 5120 5120>;

			PS_Config_Lmt_Open_Rawdata_N = <
				1527	1701	1681	1658	1646	1643	1650	1613	1679	1730	1723	1726	1698	1696	1690	1511
				1616	1710	1677	1654	1644	1640	1645	1626	1704	1735	1725	1732	1704	1703	1707	1601
				1686	1690	1657	1630	1623	1617	1624	1621	1702	1702	1696	1700	1676	1679	1694	1667
				1681	1686	1653	1621	1612	1607	1616	1599	1687	1692	1684	1690	1672	1674	1693	1654
				1664	1673	1635	1606	1602	1594	1602	1596	1641	1648	1644	1648	1629	1641	1657	1635
				1650	1660	1618	1593	1585	1577	1583	1577	1636	1644	1641	1642	1629	1643	1659	1637
				1637	1651	1611	1581	1575	1569	1573	1567	1625	1635	1629	1635	1622	1635	1654	1635
				1627	1645	1602	1569	1564	1560	1553	1558	1620	1630	1623	1629	1615	1629	1637	1630
				1623	1639	1599	1566	1562	1555	1564	1557	1596	1603	1597	1600	1594	1608	1632	1611
				1609	1625	1585	1551	1547	1541	1549	1540	1589	1596	1591	1594	1590	1602	1630	1608
				1609	1630	1586	1555	1549	1533	1552	1543	1566	1577	1572	1573	1573	1576	1614	1595
				1585	1602	1557	1529	1522	1516	1526	1516	1550	1561	1555	1557	1560	1576	1603	1586
				1573	1592	1552	1520	1513	1510	1517	1507	1538	1549	1542	1545	1550	1563	1594	1577
				1561	1581	1542	1508	1501	1500	1504	1494	1522	1533	1525	1528	1534	1549	1580	1563
				1555	1572	1535	1500	1485	1491	1498	1488	1498	1507	1502	1504	1502	1530	1561	1544
				1535	1550	1515	1481	1474	1471	1477	1467	1486	1495	1491	1492	1501	1519	1554	1535
				1521	1537	1501	1468	1462	1459	1464	1455	1464	1474	1468	1470	1477	1501	1534	1518
				1513	1530	1490	1450	1452	1448	1454	1446	1443	1455	1449	1443	1458	1485	1519	1504
				1490	1506	1471	1446	1440	1439	1443	1432	1425	1435	1429	1431	1440	1474	1513	1500
				1482	1499	1465	1439	1433	1432	1434	1427	1398	1408	1404	1408	1414	1449	1489	1476
				1456	1469	1434	1412	1408	1404	1406	1398	1385	1392	1390	1392	1399	1434	1477	1464
				1459	1470	1428	1413	1408	1404	1406	1398	1357	1364	1356	1365	1373	1408	1455	1441
				1438	1450	1413	1390	1386	1382	1383	1375	1339	1347	1347	1348	1356	1392	1439	1428
				1419	1431	1392	1370	1368	1365	1365	1359	1314	1321	1323	1324	1330	1368	1414	1404
				1401	1410	1375	1351	1349	1347	1346	1339	1303	1310	1310	1312	1320	1356	1405	1396
				1376	1378	1350	1324	1324	1323	1321	1315	1282	1282	1289	1292	1299	1335	1385	1377
				1354	1361	1324	1299	1300	1299	1299	1291	1259	1266	1267	1269	1276	1312	1364	1357
				1348	1356	1318	1293	1295	1292	1291	1284	1237	1244	1246	1247	1255	1290	1344	1339
				1314	1329	1290	1266	1267	1266	1264	1260	1207	1219	1220	1222	1229	1266	1317	1315
				1300	1309	1267	1243	1246	1244	1242	1237	1191	1198	1200	1201	1208	1245	1296	1297
				1287	1294	1255	1228	1234	1232	1229	1222	1176	1182	1183	1186	1192	1228	1279	1281
				1261	1268	1228	1200	1207	1205	1203	1195	1155	1162	1162	1165	1173	1208	1261	1262
				1261	1268	1226	1198	1206	1204	1204	1195	1140	1147	1149	1150	1157	1195	1249	1252
				1244	1251	1209	1181	1188	1186	1187	1180	1121	1127	1129	1129	1136	1174	1229	1232
				1139	1248	1202	1175	1183	1183	1183	1176	1123	1131	1130	1131	1138	1177	1233	1138
				1186	1213	1167	1140	1148	1148	1149	1143	1089	1098	1095	1095	1102	1143	1200	1188
				(-511) (-511) (-511)>;

			PS_Config_Lmt_FW_Rawdata_P = <
				1115	1113	1125	1114	1118	1115	1104	1118	1120	1121	1131	1120	1113	1101	1127	1106
				1121	1118	1111	1111	1118	1118	1117	1115	1108	1093	1103	1092	1114	1127	1134	1096
				1134	1124	1117	1132	1118	1120	1127	1124	1122	1129	1118	1125	1127	1117	1104	1128
				1120	1104	1104	1097	1120	1113	1100	1104	1117	1111	1125	1120	1118	1127	1120	1124
				1125	1120	1115	1115	1115	1110	1117	1117	1124	1114	1125	1127	1121	1120	1122	1115
				1107	1127	1131	1131	1124	1121	1129	1135	1117	1124	1128	1115	1111	1128	1118	1135
				1121	1122	1127	1132	1124	1127	1128	1122	1111	1111	1135	1114	1115	1135	1124	1107
				1128	1107	1106	1113	1106	1107	1127	1135	1107	1114	1127	1136	1131	1131	1132	1134
				1108	1103	1100	1103	1103	1100	1111	1115	1125	1118	1111	1115	1115	1111	1114	1114
				1100	1120	1125	1122	1127	1120	1125	1108	1115	1120	1134	1138	1135	1138	1134	1131
				1138	1128	1127	1129	1129	1132	1129	1131	1120	1121	1113	1122	1132	1128	1125	1117
				1107	1128	1120	1122	1121	1125	1131	1122	1128	1129	1120	1122	1118	1118	1111	1118
				1108	1114	1111	1117	1111	1111	1117	1111	1115	1114	1118	1114	1127	1117	1118	1121
				1104	1125	1124	1124	1113	1125	1113	1111	1113	1111	1111	1121	1103	1106	1115	1100
				1114	1122	1120	1125	1128	1115	1124	1127	1092	1097	1131	1096	1129	1136	1135	1099
				1121	1097	1106	1101	1094	1096	1104	1124	1117	1115	1120	1117	1115	1118	1120	1115
				1127	1117	1120	1114	1118	1115	1122	1118	1125	1124	1131	1131	1127	1132	1125	1120
				1121	1113	1113	1111	1118	1121	1121	1136	1111	1110	1110	1117	1108	1115	1111	1118
				1121	1110	1110	1107	1111	1117	1121	1122	1145	1111	1106	1106	1103	1103	1096	1135
				1122	1110	1113	1118	1117	1120	1115	1111	1117	1113	1107	1108	1104	1107	1103	1128
				1114	1128	1107	1113	1110	1118	1110	1115	1114	1124	1117	1113	1113	1111	1111	1131
				1114	1115	1129	1122	1121	1128	1114	1124	1128	1131	1122	1121	1127	1124	1117	1113
				1113	1094	1099	1100	1101	1094	1099	1106	1122	1103	1114	1103	1107	1110	1107	1122
				1106	1132	1125	1128	1136	1108	1111	1113	1114	1117	1115	1111	1118	1117	1117	1131
				1118	1097	1092	1092	1092	1103	1099	1101	1125	1125	1132	1122	1121	1118	1125	1127
				1110	1110	1104	1117	1111	1104	1103	1122	1128	1127	1122	1111	1111	1113	1114	1134
				1103	1117	1114	1107	1120	1092	1086	1094	1121	1117	1113	1101	1104	1107	1106	1128
				1101	1097	1097	1092	1097	1106	1103	1132	1104	1100	1101	1107	1114	1114	1114	1110
				1110	1117	1120	1110	1124	1120	1113	1110	1104	1128	1139	1129	1131	1132	1134	1121
				1134	1117	1120	1117	1115	1134	1128	1104	1120	1107	1110	1115	1111	1107	1111	1120
				1108	1122	1128	1120	1122	1121	1117	1104	1118	1114	1107	1132	1129	1115	1111	1104
				1121	1117	1124	1120	1118	1124	1124	1114	1136	1128	1124	1111	1120	1122	1108	1136
				1128	1121	1122	1121	1122	1125	1127	1121	1125	1125	1122	1107	1118	1113	1106	1132
				1104	1125	1110	1097	1127	1101	1096	1138	1120	1122	1127	1118	1127	1121	1121	1117
				1113	1114	1110	1117	1120	1121	1127	1124	1120	1125	1121	1122	1122	1120	1117	1114
				1118	1118	1094	1110	1120	1121	1125	1114	1099	1118	1139	1142	1132	1118	1121	1125
				2560 2560 2560>;

			PS_Config_Lmt_FW_Rawdata_N = <
				478	477	482	477	479	478	473	479	480	480	484	480	477	472	483	474
				480	479	476	476	479	479	478	478	475	468	472	468	477	483	486	469
				486	481	478	485	479	480	483	481	481	484	479	482	483	478	473	483
				480	473	473	470	480	477	471	473	478	476	482	480	479	483	480	481
				482	480	478	478	478	475	478	478	481	477	482	483	480	480	481	478
				474	483	484	484	481	480	484	486	478	481	483	478	476	483	479	486
				480	481	483	485	481	483	483	481	476	476	486	477	478	486	481	474
				483	474	474	477	474	474	483	486	474	477	483	487	484	484	485	486
				475	472	471	472	472	471	476	478	482	479	476	478	478	476	477	477
				471	480	482	481	483	480	482	475	478	480	486	487	486	487	486	484
				487	483	483	484	484	485	484	484	480	480	477	481	485	483	482	478
				474	483	480	481	480	482	484	481	483	484	480	481	479	479	476	479
				475	477	476	478	476	476	478	476	478	477	479	477	483	478	479	480
				473	482	481	481	477	482	477	476	477	476	476	480	472	474	478	471
				477	481	480	482	483	478	481	483	468	470	484	469	484	487	486	471
				480	470	474	472	469	469	473	481	478	478	480	478	478	479	480	478
				483	478	480	477	479	478	481	479	482	481	484	484	483	485	482	480
				480	477	477	476	479	480	480	487	476	475	475	478	475	478	476	479
				480	475	475	474	476	478	480	481	490	476	474	474	472	472	469	486
				481	475	477	479	478	480	478	476	478	477	474	475	473	474	472	483
				477	483	474	477	475	479	475	478	477	481	478	477	477	476	476	484
				477	478	484	481	480	483	477	481	483	484	481	480	483	481	478	477
				477	469	471	471	472	469	471	474	481	472	477	472	474	475	474	481
				474	485	482	483	487	475	476	477	477	478	478	476	479	478	478	484
				479	470	468	468	468	472	471	472	482	482	485	481	480	479	482	483
				475	475	473	478	476	473	472	481	483	483	481	476	476	477	477	486
				472	478	477	474	480	468	465	469	480	478	477	472	473	474	474	483
				472	470	470	468	470	474	472	485	473	471	472	474	477	477	477	475
				475	478	480	475	481	480	477	475	473	483	488	484	484	485	486	480
				486	478	480	478	478	486	483	473	480	474	475	478	476	474	476	480
				475	481	483	480	481	480	478	473	479	477	474	485	484	478	476	473
				480	478	481	480	479	481	481	477	487	483	481	476	480	481	475	487
				483	480	481	480	481	482	483	480	482	482	481	474	479	477	474	485
				473	482	475	470	483	472	469	487	480	481	483	479	483	480	480	478
				477	477	475	478	480	480	483	481	480	482	480	481	481	480	478	477
				479	479	469	475	480	480	482	477	471	479	488	489	485	479	480	482
				240 240 240>;

			PS_Config_Lmt_FW_CC_P = <
				51	49	49	49	49	49	49	49	51	51	51	49	49	49	49	51
				51	49	49	49	49	49	49	51	51	51	51	51	49	49	49	51
				49	49	49	49	49	49	49	49	51	51	51	51	51	49	49	51
				51	51	51	51	51	51	51	51	51	51	51	51	51	49	49	51
				51	49	49	49	49	49	51	49	51	51	49	49	51	49	49	51
				51	51	51	51	51	51	51	51	51	51	51	51	51	51	49	51
				51	49	49	49	49	49	51	51	51	51	51	51	51	51	49	51
				51	51	51	51	51	51	51	51	51	51	51	51	51	51	51	51
				51	49	49	51	49	49	51	51	51	51	51	51	51	49	49	51
				51	51	51	51	51	51	51	51	51	51	51	51	51	51	51	51
				51	49	49	49	51	49	51	51	51	51	51	51	51	51	51	51
				51	51	51	51	51	51	51	51	51	51	51	51	51	51	51	51
				51	49	49	49	49	49	49	51	51	51	51	51	51	51	51	51
				51	51	51	51	51	51	51	51	51	51	51	51	51	51	51	51
				51	51	51	51	51	51	51	51	51	51	51	51	51	51	51	51
				51	51	51	51	51	51	51	51	51	51	51	51	51	51	51	51
				51	49	51	49	49	51	51	51	51	51	51	51	51	51	51	51
				51	51	51	51	51	51	51	51	51	51	51	51	51	51	51	51
				51	51	51	51	51	51	51	51	51	51	51	51	51	51	51	51
				51	51	51	51	51	51	51	52	51	51	51	51	51	51	51	51
				51	49	51	51	51	51	51	51	51	51	51	51	51	51	51	51
				51	51	51	51	51	51	51	51	51	51	51	51	51	51	51	51
				51	51	51	51	51	51	51	51	51	51	51	51	51	51	51	51
				51	51	51	51	51	51	51	51	51	51	51	51	51	51	51	51
				51	51	51	51	51	51	51	51	51	51	51	51	51	51	51	51
				51	51	51	51	51	51	51	51	51	51	51	51	51	51	51	51
				51	51	51	51	51	51	51	51	51	51	51	51	51	51	51	51
				51	51	51	51	51	51	51	52	51	51	51	51	51	51	51	51
				51	51	51	51	51	51	51	51	51	51	51	51	51	51	51	51
				51	51	51	51	51	51	51	52	51	51	51	51	51	51	51	51
				51	51	51	51	51	51	51	51	52	51	51	51	51	51	51	51
				51	51	51	51	51	51	51	52	51	51	51	51	51	51	51	51
				51	51	51	51	51	51	51	51	52	51	51	51	51	51	51	51
				51	51	51	51	51	51	51	52	51	51	51	51	51	51	51	51
				51	51	51	51	51	51	51	51	52	51	51	51	51	51	51	51
				52	51	51	51	51	51	51	52	52	51	51	51	51	51	51	52
				314 314 314>;

			PS_Config_Lmt_FW_CC_N = <
				22	22	22	22	22	22	22	22	22	22	22	22	22	22	22	22
				22	22	22	22	22	22	22	22	22	22	22	22	22	22	22	22
				22	22	22	22	22	22	22	22	22	22	22	22	22	22	22	22
				22	22	22	22	22	22	22	22	22	22	22	22	22	22	22	22
				22	22	22	22	22	22	22	22	22	22	22	22	22	22	22	22
				22	22	22	22	22	22	22	22	22	22	22	22	22	22	22	22
				22	22	22	22	22	22	22	22	22	22	22	22	22	22	22	22
				22	22	22	22	22	22	22	22	22	22	22	22	22	22	22	22
				22	22	22	22	22	22	22	22	22	22	22	22	22	22	22	22
				22	22	22	22	22	22	22	22	22	22	22	22	22	22	22	22
				22	22	22	22	22	22	22	22	22	22	22	22	22	22	22	22
				22	22	22	22	22	22	22	22	22	22	22	22	22	22	22	22
				22	22	22	22	22	22	22	22	22	22	22	22	22	22	22	22
				22	22	22	22	22	22	22	22	22	22	22	22	22	22	22	22
				22	22	22	22	22	22	22	22	22	22	22	22	22	22	22	22
				22	22	22	22	22	22	22	22	22	22	22	22	22	22	22	22
				22	22	22	22	22	22	22	22	22	22	22	22	22	22	22	22
				22	22	22	22	22	22	22	22	22	22	22	22	22	22	22	22
				22	22	22	22	22	22	22	22	22	22	22	22	22	22	22	22
				22	22	22	22	22	22	22	23	22	22	22	22	22	22	22	22
				22	22	22	22	22	22	22	22	22	22	22	22	22	22	22	22
				22	22	22	22	22	22	22	22	22	22	22	22	22	22	22	22
				22	22	22	22	22	22	22	22	22	22	22	22	22	22	22	22
				22	22	22	22	22	22	22	22	22	22	22	22	22	22	22	22
				22	22	22	22	22	22	22	22	22	22	22	22	22	22	22	22
				22	22	22	22	22	22	22	22	22	22	22	22	22	22	22	22
				22	22	22	22	22	22	22	22	22	22	22	22	22	22	22	22
				22	22	22	22	22	22	22	23	22	22	22	22	22	22	22	22
				22	22	22	22	22	22	22	22	22	22	22	22	22	22	22	22
				22	22	22	22	22	22	22	23	22	22	22	22	22	22	22	22
				22	22	22	22	22	22	22	22	23	22	22	22	22	22	22	22
				22	22	22	22	22	22	22	23	22	22	22	22	22	22	22	22
				22	22	22	22	22	22	22	22	23	22	22	22	22	22	22	22
				22	22	22	22	22	22	22	23	22	22	22	22	22	22	22	22
				22	22	22	22	22	22	22	22	23	22	22	22	22	22	22	22
				23	22	22	22	22	22	22	23	23	22	22	22	22	22	22	23
				0 0 0>;

			PS_Config_Lmt_FW_Diff_P = <
				50	50	50	50	50	50	50	50	50	50	50	50	50	50	50	50
				50	50	50	50	50	50	50	50	50	50	50	50	50	50	50	50
				50	50	50	50	50	50	50	50	50	50	50	50	50	50	50	50
				50	50	50	50	50	50	50	50	50	50	50	50	50	50	50	50
				50	50	50	50	50	50	50	50	50	50	50	50	50	50	50	50
				50	50	50	50	50	50	50	50	50	50	50	50	50	50	50	50
				50	50	50	50	50	50	50	50	50	50	50	50	50	50	50	50
				50	50	50	50	50	50	50	50	50	50	50	50	50	50	50	50
				50	50	50	50	50	50	50	50	50	50	50	50	50	50	50	50
				50	50	50	50	50	50	50	50	50	50	50	50	50	50	50	50
				50	50	50	50	50	50	50	50	50	50	50	50	50	50	50	50
				50	50	50	50	50	50	50	50	50	50	50	50	50	50	50	50
				50	50	50	50	50	50	50	50	50	50	50	50	50	50	50	50
				50	50	50	50	50	50	50	50	50	50	50	50	50	50	50	50
				50	50	50	50	50	50	50	50	50	50	50	50	50	50	50	50
				50	50	50	50	50	50	50	50	50	50	50	50	50	50	50	50
				50	50	50	50	50	50	50	50	50	50	50	50	50	50	50	50
				50	50	50	50	50	50	50	50	50	50	50	50	50	50	50	50
				50	50	50	50	50	50	50	50	50	50	50	50	50	50	50	50
				50	50	50	50	50	50	50	50	50	50	50	50	50	50	50	50
				50	50	50	50	50	50	50	50	50	50	50	50	50	50	50	50
				50	50	50	50	50	50	50	50	50	50	50	50	50	50	50	50
				50	50	50	50	50	50	50	50	50	50	50	50	50	50	50	50
				50	50	50	50	50	50	50	50	50	50	50	50	50	50	50	50
				50	50	50	50	50	50	50	50	50	50	50	50	50	50	50	50
				50	50	50	50	50	50	50	50	50	50	50	50	50	50	50	50
				50	50	50	50	50	50	50	50	50	50	50	50	50	50	50	50
				50	50	50	50	50	50	50	50	50	50	50	50	50	50	50	50
				50	50	50	50	50	50	50	50	50	50	50	50	50	50	50	50
				50	50	50	50	50	50	50	50	50	50	50	50	50	50	50	50
				50	50	50	50	50	50	50	50	50	50	50	50	50	50	50	50
				50	50	50	50	50	50	50	50	50	50	50	50	50	50	50	50
				50	50	50	50	50	50	50	50	50	50	50	50	50	50	50	50
				50	50	50	50	50	50	50	50	50	50	50	50	50	50	50	50
				50	50	50	50	50	50	50	50	50	50	50	50	50	50	50	50
				50	50	50	50	50	50	50	50	50	50	50	50	50	50	50	50
				75 75 75>;

			PS_Config_Lmt_FW_Diff_N = <
				(-50)	(-50)	(-50)	(-50)	(-50)	(-50)	(-50)	(-50)	(-50)	(-50)	(-50)	(-50)	(-50)	(-50)	(-50)	(-50)
				(-50)	(-50)	(-50)	(-50)	(-50)	(-50)	(-50)	(-50)	(-50)	(-50)	(-50)	(-50)	(-50)	(-50)	(-50)	(-50)
				(-50)	(-50)	(-50)	(-50)	(-50)	(-50)	(-50)	(-50)	(-50)	(-50)	(-50)	(-50)	(-50)	(-50)	(-50)	(-50)
				(-50)	(-50)	(-50)	(-50)	(-50)	(-50)	(-50)	(-50)	(-50)	(-50)	(-50)	(-50)	(-50)	(-50)	(-50)	(-50)
				(-50)	(-50)	(-50)	(-50)	(-50)	(-50)	(-50)	(-50)	(-50)	(-50)	(-50)	(-50)	(-50)	(-50)	(-50)	(-50)
				(-50)	(-50)	(-50)	(-50)	(-50)	(-50)	(-50)	(-50)	(-50)	(-50)	(-50)	(-50)	(-50)	(-50)	(-50)	(-50)
				(-50)	(-50)	(-50)	(-50)	(-50)	(-50)	(-50)	(-50)	(-50)	(-50)	(-50)	(-50)	(-50)	(-50)	(-50)	(-50)
				(-50)	(-50)	(-50)	(-50)	(-50)	(-50)	(-50)	(-50)	(-50)	(-50)	(-50)	(-50)	(-50)	(-50)	(-50)	(-50)
				(-50)	(-50)	(-50)	(-50)	(-50)	(-50)	(-50)	(-50)	(-50)	(-50)	(-50)	(-50)	(-50)	(-50)	(-50)	(-50)
				(-50)	(-50)	(-50)	(-50)	(-50)	(-50)	(-50)	(-50)	(-50)	(-50)	(-50)	(-50)	(-50)	(-50)	(-50)	(-50)
				(-50)	(-50)	(-50)	(-50)	(-50)	(-50)	(-50)	(-50)	(-50)	(-50)	(-50)	(-50)	(-50)	(-50)	(-50)	(-50)
				(-50)	(-50)	(-50)	(-50)	(-50)	(-50)	(-50)	(-50)	(-50)	(-50)	(-50)	(-50)	(-50)	(-50)	(-50)	(-50)
				(-50)	(-50)	(-50)	(-50)	(-50)	(-50)	(-50)	(-50)	(-50)	(-50)	(-50)	(-50)	(-50)	(-50)	(-50)	(-50)
				(-50)	(-50)	(-50)	(-50)	(-50)	(-50)	(-50)	(-50)	(-50)	(-50)	(-50)	(-50)	(-50)	(-50)	(-50)	(-50)
				(-50)	(-50)	(-50)	(-50)	(-50)	(-50)	(-50)	(-50)	(-50)	(-50)	(-50)	(-50)	(-50)	(-50)	(-50)	(-50)
				(-50)	(-50)	(-50)	(-50)	(-50)	(-50)	(-50)	(-50)	(-50)	(-50)	(-50)	(-50)	(-50)	(-50)	(-50)	(-50)
				(-50)	(-50)	(-50)	(-50)	(-50)	(-50)	(-50)	(-50)	(-50)	(-50)	(-50)	(-50)	(-50)	(-50)	(-50)	(-50)
				(-50)	(-50)	(-50)	(-50)	(-50)	(-50)	(-50)	(-50)	(-50)	(-50)	(-50)	(-50)	(-50)	(-50)	(-50)	(-50)
				(-50)	(-50)	(-50)	(-50)	(-50)	(-50)	(-50)	(-50)	(-50)	(-50)	(-50)	(-50)	(-50)	(-50)	(-50)	(-50)
				(-50)	(-50)	(-50)	(-50)	(-50)	(-50)	(-50)	(-50)	(-50)	(-50)	(-50)	(-50)	(-50)	(-50)	(-50)	(-50)
				(-50)	(-50)	(-50)	(-50)	(-50)	(-50)	(-50)	(-50)	(-50)	(-50)	(-50)	(-50)	(-50)	(-50)	(-50)	(-50)
				(-50)	(-50)	(-50)	(-50)	(-50)	(-50)	(-50)	(-50)	(-50)	(-50)	(-50)	(-50)	(-50)	(-50)	(-50)	(-50)
				(-50)	(-50)	(-50)	(-50)	(-50)	(-50)	(-50)	(-50)	(-50)	(-50)	(-50)	(-50)	(-50)	(-50)	(-50)	(-50)
				(-50)	(-50)	(-50)	(-50)	(-50)	(-50)	(-50)	(-50)	(-50)	(-50)	(-50)	(-50)	(-50)	(-50)	(-50)	(-50)
				(-50)	(-50)	(-50)	(-50)	(-50)	(-50)	(-50)	(-50)	(-50)	(-50)	(-50)	(-50)	(-50)	(-50)	(-50)	(-50)
				(-50)	(-50)	(-50)	(-50)	(-50)	(-50)	(-50)	(-50)	(-50)	(-50)	(-50)	(-50)	(-50)	(-50)	(-50)	(-50)
				(-50)	(-50)	(-50)	(-50)	(-50)	(-50)	(-50)	(-50)	(-50)	(-50)	(-50)	(-50)	(-50)	(-50)	(-50)	(-50)
				(-50)	(-50)	(-50)	(-50)	(-50)	(-50)	(-50)	(-50)	(-50)	(-50)	(-50)	(-50)	(-50)	(-50)	(-50)	(-50)
				(-50)	(-50)	(-50)	(-50)	(-50)	(-50)	(-50)	(-50)	(-50)	(-50)	(-50)	(-50)	(-50)	(-50)	(-50)	(-50)
				(-50)	(-50)	(-50)	(-50)	(-50)	(-50)	(-50)	(-50)	(-50)	(-50)	(-50)	(-50)	(-50)	(-50)	(-50)	(-50)
				(-50)	(-50)	(-50)	(-50)	(-50)	(-50)	(-50)	(-50)	(-50)	(-50)	(-50)	(-50)	(-50)	(-50)	(-50)	(-50)
				(-50)	(-50)	(-50)	(-50)	(-50)	(-50)	(-50)	(-50)	(-50)	(-50)	(-50)	(-50)	(-50)	(-50)	(-50)	(-50)
				(-50)	(-50)	(-50)	(-50)	(-50)	(-50)	(-50)	(-50)	(-50)	(-50)	(-50)	(-50)	(-50)	(-50)	(-50)	(-50)
				(-50)	(-50)	(-50)	(-50)	(-50)	(-50)	(-50)	(-50)	(-50)	(-50)	(-50)	(-50)	(-50)	(-50)	(-50)	(-50)
				(-50)	(-50)	(-50)	(-50)	(-50)	(-50)	(-50)	(-50)	(-50)	(-50)	(-50)	(-50)	(-50)	(-50)	(-50)	(-50)
				(-50)	(-50)	(-50)	(-50)	(-50)	(-50)	(-50)	(-50)	(-50)	(-50)	(-50)	(-50)	(-50)	(-50)	(-50)	(-50)
				(-75) (-75) (-75)>;

			PS_Config_Lmt_PenTipX_FW_Raw_P = <
				570 570 570 570 570 570 570 570 570 570 570 570 570 570 570 570 570 570 570 570 570 570 570 570 570 570 570 570 570 570 570 570
				570 570 570 570 570 570 570 570 570 570 570 570 570 570 570 570 570 570 570 570 570 570 570 570 570 570 570 570 570 570 570 570
				570 570 570 570 570 570 570 570 570 570 570 570 570 570 570 570 570 570 570 570 570 570 570 570 570 570 570 570 570 570 570 570
				570 570 570 570 570 570 570 570 570 570 570 570 570 570 570 570 570 570 570 570 570 570 570 570 570 570 570 570 570 570 570 570
				570 570 570 570 570 570 570 570 570 570 570 570 570 570 570 570 570 570 570 570 570 570 570 570 570 570 570 570 570 570 570 570
				570 570 570 570 570 570 570 570 570 570 570 570 570 570 570 570 570 570 570 570 570 570 570 570 570 570 570 570 570 570 570 570>;

			PS_Config_Lmt_PenTipX_FW_Raw_N = <
				(-570) (-570) (-570) (-570) (-570) (-570) (-570) (-570) (-570) (-570) (-570) (-570) (-570) (-570) (-570) (-570) (-570) (-570) (-570) (-570) (-570) (-570) (-570) (-570) (-570) (-570) (-570) (-570) (-570) (-570) (-570) (-570)
				(-570) (-570) (-570) (-570) (-570) (-570) (-570) (-570) (-570) (-570) (-570) (-570) (-570) (-570) (-570) (-570) (-570) (-570) (-570) (-570) (-570) (-570) (-570) (-570) (-570) (-570) (-570) (-570) (-570) (-570) (-570) (-570)
				(-570) (-570) (-570) (-570) (-570) (-570) (-570) (-570) (-570) (-570) (-570) (-570) (-570) (-570) (-570) (-570) (-570) (-570) (-570) (-570) (-570) (-570) (-570) (-570) (-570) (-570) (-570) (-570) (-570) (-570) (-570) (-570)
				(-570) (-570) (-570) (-570) (-570) (-570) (-570) (-570) (-570) (-570) (-570) (-570) (-570) (-570) (-570) (-570) (-570) (-570) (-570) (-570) (-570) (-570) (-570) (-570) (-570) (-570) (-570) (-570) (-570) (-570) (-570) (-570)
				(-570) (-570) (-570) (-570) (-570) (-570) (-570) (-570) (-570) (-570) (-570) (-570) (-570) (-570) (-570) (-570) (-570) (-570) (-570) (-570) (-570) (-570) (-570) (-570) (-570) (-570) (-570) (-570) (-570) (-570) (-570) (-570)
				(-570) (-570) (-570) (-570) (-570) (-570) (-570) (-570) (-570) (-570) (-570) (-570) (-570) (-570) (-570) (-570) (-570) (-570) (-570) (-570) (-570) (-570) (-570) (-570) (-570) (-570) (-570) (-570) (-570) (-570) (-570) (-570)>;

			PS_Config_Lmt_PenTipY_FW_Raw_P = <
				570 570 570 570
				570 570 570 570
				570 570 570 570
				570 570 570 570
				570 570 570 570
				570 570 570 570
				570 570 570 570
				570 570 570 570
				570 570 570 570
				570 570 570 570
				570 570 570 570
				570 570 570 570
				570 570 570 570
				570 570 570 570
				570 570 570 570
				570 570 570 570
				570 570 570 570
				570 570 570 570
				570 570 570 570
				570 570 570 570
				570 570 570 570
				570 570 570 570
				570 570 570 570
				570 570 570 570
				570 570 570 570
				570 570 570 570
				570 570 570 570
				570 570 570 570
				570 570 570 570
				570 570 570 570
				570 570 570 570
				570 570 570 570
				570 570 570 570
				570 570 570 570
				570 570 570 570
				570 570 570 570
				570 570 570 570
				570 570 570 570
				570 570 570 570
				570 570 570 570
				570 570 570 570
				570 570 570 570
				570 570 570 570
				570 570 570 570
				570 570 570 570
				570 570 570 570
				570 570 570 570
				570 570 570 570
				570 570 570 570
				570 570 570 570>;

			PS_Config_Lmt_PenTipY_FW_Raw_N = <
				(-570) (-570) (-570) (-570)
				(-570) (-570) (-570) (-570)
				(-570) (-570) (-570) (-570)
				(-570) (-570) (-570) (-570)
				(-570) (-570) (-570) (-570)
				(-570) (-570) (-570) (-570)
				(-570) (-570) (-570) (-570)
				(-570) (-570) (-570) (-570)
				(-570) (-570) (-570) (-570)
				(-570) (-570) (-570) (-570)
				(-570) (-570) (-570) (-570)
				(-570) (-570) (-570) (-570)
				(-570) (-570) (-570) (-570)
				(-570) (-570) (-570) (-570)
				(-570) (-570) (-570) (-570)
				(-570) (-570) (-570) (-570)
				(-570) (-570) (-570) (-570)
				(-570) (-570) (-570) (-570)
				(-570) (-570) (-570) (-570)
				(-570) (-570) (-570) (-570)
				(-570) (-570) (-570) (-570)
				(-570) (-570) (-570) (-570)
				(-570) (-570) (-570) (-570)
				(-570) (-570) (-570) (-570)
				(-570) (-570) (-570) (-570)
				(-570) (-570) (-570) (-570)
				(-570) (-570) (-570) (-570)
				(-570) (-570) (-570) (-570)
				(-570) (-570) (-570) (-570)
				(-570) (-570) (-570) (-570)
				(-570) (-570) (-570) (-570)
				(-570) (-570) (-570) (-570)
				(-570) (-570) (-570) (-570)
				(-570) (-570) (-570) (-570)
				(-570) (-570) (-570) (-570)
				(-570) (-570) (-570) (-570)
				(-570) (-570) (-570) (-570)
				(-570) (-570) (-570) (-570)
				(-570) (-570) (-570) (-570)
				(-570) (-570) (-570) (-570)
				(-570) (-570) (-570) (-570)
				(-570) (-570) (-570) (-570)
				(-570) (-570) (-570) (-570)
				(-570) (-570) (-570) (-570)
				(-570) (-570) (-570) (-570)
				(-570) (-570) (-570) (-570)
				(-570) (-570) (-570) (-570)
				(-570) (-570) (-570) (-570)
				(-570) (-570) (-570) (-570)
				(-570) (-570) (-570) (-570)>;

			PS_Config_Lmt_PenRingX_FW_Raw_P = <
				570 570 570 570 570 570 570 570 570 570 570 570 570 570 570 570 570 570 570 570 570 570 570 570 570 570 570 570 570 570 570 570
				570 570 570 570 570 570 570 570 570 570 570 570 570 570 570 570 570 570 570 570 570 570 570 570 570 570 570 570 570 570 570 570
				570 570 570 570 570 570 570 570 570 570 570 570 570 570 570 570 570 570 570 570 570 570 570 570 570 570 570 570 570 570 570 570
				570 570 570 570 570 570 570 570 570 570 570 570 570 570 570 570 570 570 570 570 570 570 570 570 570 570 570 570 570 570 570 570
				570 570 570 570 570 570 570 570 570 570 570 570 570 570 570 570 570 570 570 570 570 570 570 570 570 570 570 570 570 570 570 570
				570 570 570 570 570 570 570 570 570 570 570 570 570 570 570 570 570 570 570 570 570 570 570 570 570 570 570 570 570 570 570 570>;

			PS_Config_Lmt_PenRingX_FW_Raw_N = <
				(-570) (-570) (-570) (-570) (-570) (-570) (-570) (-570) (-570) (-570) (-570) (-570) (-570) (-570) (-570) (-570) (-570) (-570) (-570) (-570) (-570) (-570) (-570) (-570) (-570) (-570) (-570) (-570) (-570) (-570) (-570) (-570)
				(-570) (-570) (-570) (-570) (-570) (-570) (-570) (-570) (-570) (-570) (-570) (-570) (-570) (-570) (-570) (-570) (-570) (-570) (-570) (-570) (-570) (-570) (-570) (-570) (-570) (-570) (-570) (-570) (-570) (-570) (-570) (-570)
				(-570) (-570) (-570) (-570) (-570) (-570) (-570) (-570) (-570) (-570) (-570) (-570) (-570) (-570) (-570) (-570) (-570) (-570) (-570) (-570) (-570) (-570) (-570) (-570) (-570) (-570) (-570) (-570) (-570) (-570) (-570) (-570)
				(-570) (-570) (-570) (-570) (-570) (-570) (-570) (-570) (-570) (-570) (-570) (-570) (-570) (-570) (-570) (-570) (-570) (-570) (-570) (-570) (-570) (-570) (-570) (-570) (-570) (-570) (-570) (-570) (-570) (-570) (-570) (-570)
				(-570) (-570) (-570) (-570) (-570) (-570) (-570) (-570) (-570) (-570) (-570) (-570) (-570) (-570) (-570) (-570) (-570) (-570) (-570) (-570) (-570) (-570) (-570) (-570) (-570) (-570) (-570) (-570) (-570) (-570) (-570) (-570)
				(-570) (-570) (-570) (-570) (-570) (-570) (-570) (-570) (-570) (-570) (-570) (-570) (-570) (-570) (-570) (-570) (-570) (-570) (-570) (-570) (-570) (-570) (-570) (-570) (-570) (-570) (-570) (-570) (-570) (-570) (-570) (-570)>;

			PS_Config_Lmt_PenRingY_FW_Raw_P = <
				570 570 570 570
				570 570 570 570
				570 570 570 570
				570 570 570 570
				570 570 570 570
				570 570 570 570
				570 570 570 570
				570 570 570 570
				570 570 570 570
				570 570 570 570
				570 570 570 570
				570 570 570 570
				570 570 570 570
				570 570 570 570
				570 570 570 570
				570 570 570 570
				570 570 570 570
				570 570 570 570
				570 570 570 570
				570 570 570 570
				570 570 570 570
				570 570 570 570
				570 570 570 570
				570 570 570 570
				570 570 570 570
				570 570 570 570
				570 570 570 570
				570 570 570 570
				570 570 570 570
				570 570 570 570
				570 570 570 570
				570 570 570 570
				570 570 570 570
				570 570 570 570
				570 570 570 570
				570 570 570 570
				570 570 570 570
				570 570 570 570
				570 570 570 570
				570 570 570 570
				570 570 570 570
				570 570 570 570
				570 570 570 570
				570 570 570 570
				570 570 570 570
				570 570 570 570
				570 570 570 570
				570 570 570 570
				570 570 570 570
				570 570 570 570>;

			PS_Config_Lmt_PenRingY_FW_Raw_N = <
				(-570) (-570) (-570) (-570)
				(-570) (-570) (-570) (-570)
				(-570) (-570) (-570) (-570)
				(-570) (-570) (-570) (-570)
				(-570) (-570) (-570) (-570)
				(-570) (-570) (-570) (-570)
				(-570) (-570) (-570) (-570)
				(-570) (-570) (-570) (-570)
				(-570) (-570) (-570) (-570)
				(-570) (-570) (-570) (-570)
				(-570) (-570) (-570) (-570)
				(-570) (-570) (-570) (-570)
				(-570) (-570) (-570) (-570)
				(-570) (-570) (-570) (-570)
				(-570) (-570) (-570) (-570)
				(-570) (-570) (-570) (-570)
				(-570) (-570) (-570) (-570)
				(-570) (-570) (-570) (-570)
				(-570) (-570) (-570) (-570)
				(-570) (-570) (-570) (-570)
				(-570) (-570) (-570) (-570)
				(-570) (-570) (-570) (-570)
				(-570) (-570) (-570) (-570)
				(-570) (-570) (-570) (-570)
				(-570) (-570) (-570) (-570)
				(-570) (-570) (-570) (-570)
				(-570) (-570) (-570) (-570)
				(-570) (-570) (-570) (-570)
				(-570) (-570) (-570) (-570)
				(-570) (-570) (-570) (-570)
				(-570) (-570) (-570) (-570)
				(-570) (-570) (-570) (-570)
				(-570) (-570) (-570) (-570)
				(-570) (-570) (-570) (-570)
				(-570) (-570) (-570) (-570)
				(-570) (-570) (-570) (-570)
				(-570) (-570) (-570) (-570)
				(-570) (-570) (-570) (-570)
				(-570) (-570) (-570) (-570)
				(-570) (-570) (-570) (-570)
				(-570) (-570) (-570) (-570)
				(-570) (-570) (-570) (-570)
				(-570) (-570) (-570) (-570)
				(-570) (-570) (-570) (-570)
				(-570) (-570) (-570) (-570)
				(-570) (-570) (-570) (-570)
				(-570) (-570) (-570) (-570)
				(-570) (-570) (-570) (-570)
				(-570) (-570) (-570) (-570)
				(-570) (-570) (-570) (-570)>;

			PS_Config_Lmt_PenTipX_FW_Diff_P = <
				870 870 870 870 870 870 870 870 870 870 870 870 870 870 870 870 870 870 870 870 870 870 870 870 870 870 870 870 870 870 870 870
				870 870 870 870 870 870 870 870 870 870 870 870 870 870 870 870 870 870 870 870 870 870 870 870 870 870 870 870 870 870 870 870
				870 870 870 870 870 870 870 870 870 870 870 870 870 870 870 870 870 870 870 870 870 870 870 870 870 870 870 870 870 870 870 870
				870 870 870 870 870 870 870 870 870 870 870 870 870 870 870 870 870 870 870 870 870 870 870 870 870 870 870 870 870 870 870 870
				870 870 870 870 870 870 870 870 870 870 870 870 870 870 870 870 870 870 870 870 870 870 870 870 870 870 870 870 870 870 870 870
				870 870 870 870 870 870 870 870 870 870 870 870 870 870 870 870 870 870 870 870 870 870 870 870 870 870 870 870 870 870 870 870>;

			PS_Config_Lmt_PenTipX_FW_Diff_N = <
				(-870) (-870) (-870) (-870) (-870) (-870) (-870) (-870) (-870) (-870) (-870) (-870) (-870) (-870) (-870) (-870) (-870) (-870) (-870) (-870) (-870) (-870) (-870) (-870) (-870) (-870) (-870) (-870) (-870) (-870) (-870) (-870)
				(-870) (-870) (-870) (-870) (-870) (-870) (-870) (-870) (-870) (-870) (-870) (-870) (-870) (-870) (-870) (-870) (-870) (-870) (-870) (-870) (-870) (-870) (-870) (-870) (-870) (-870) (-870) (-870) (-870) (-870) (-870) (-870)
				(-870) (-870) (-870) (-870) (-870) (-870) (-870) (-870) (-870) (-870) (-870) (-870) (-870) (-870) (-870) (-870) (-870) (-870) (-870) (-870) (-870) (-870) (-870) (-870) (-870) (-870) (-870) (-870) (-870) (-870) (-870) (-870)
				(-870) (-870) (-870) (-870) (-870) (-870) (-870) (-870) (-870) (-870) (-870) (-870) (-870) (-870) (-870) (-870) (-870) (-870) (-870) (-870) (-870) (-870) (-870) (-870) (-870) (-870) (-870) (-870) (-870) (-870) (-870) (-870)
				(-870) (-870) (-870) (-870) (-870) (-870) (-870) (-870) (-870) (-870) (-870) (-870) (-870) (-870) (-870) (-870) (-870) (-870) (-870) (-870) (-870) (-870) (-870) (-870) (-870) (-870) (-870) (-870) (-870) (-870) (-870) (-870)
				(-870) (-870) (-870) (-870) (-870) (-870) (-870) (-870) (-870) (-870) (-870) (-870) (-870) (-870) (-870) (-870) (-870) (-870) (-870) (-870) (-870) (-870) (-870) (-870) (-870) (-870) (-870) (-870) (-870) (-870) (-870) (-870)>;

			PS_Config_Lmt_PenTipY_FW_Diff_P = <
				870 870 870 870
				870 870 870 870
				870 870 870 870
				870 870 870 870
				870 870 870 870
				870 870 870 870
				870 870 870 870
				870 870 870 870
				870 870 870 870
				870 870 870 870
				870 870 870 870
				870 870 870 870
				870 870 870 870
				870 870 870 870
				870 870 870 870
				870 870 870 870
				870 870 870 870
				870 870 870 870
				870 870 870 870
				870 870 870 870
				870 870 870 870
				870 870 870 870
				870 870 870 870
				870 870 870 870
				870 870 870 870
				870 870 870 870
				870 870 870 870
				870 870 870 870
				870 870 870 870
				870 870 870 870
				870 870 870 870
				870 870 870 870
				870 870 870 870
				870 870 870 870
				870 870 870 870
				870 870 870 870
				870 870 870 870
				870 870 870 870
				870 870 870 870
				870 870 870 870
				870 870 870 870
				870 870 870 870
				870 870 870 870
				870 870 870 870
				870 870 870 870
				870 870 870 870
				870 870 870 870
				870 870 870 870
				870 870 870 870
				870 870 870 870>;

			PS_Config_Lmt_PenTipY_FW_Diff_N = <
				(-870) (-870) (-870) (-870)
				(-870) (-870) (-870) (-870)
				(-870) (-870) (-870) (-870)
				(-870) (-870) (-870) (-870)
				(-870) (-870) (-870) (-870)
				(-870) (-870) (-870) (-870)
				(-870) (-870) (-870) (-870)
				(-870) (-870) (-870) (-870)
				(-870) (-870) (-870) (-870)
				(-870) (-870) (-870) (-870)
				(-870) (-870) (-870) (-870)
				(-870) (-870) (-870) (-870)
				(-870) (-870) (-870) (-870)
				(-870) (-870) (-870) (-870)
				(-870) (-870) (-870) (-870)
				(-870) (-870) (-870) (-870)
				(-870) (-870) (-870) (-870)
				(-870) (-870) (-870) (-870)
				(-870) (-870) (-870) (-870)
				(-870) (-870) (-870) (-870)
				(-870) (-870) (-870) (-870)
				(-870) (-870) (-870) (-870)
				(-870) (-870) (-870) (-870)
				(-870) (-870) (-870) (-870)
				(-870) (-870) (-870) (-870)
				(-870) (-870) (-870) (-870)
				(-870) (-870) (-870) (-870)
				(-870) (-870) (-870) (-870)
				(-870) (-870) (-870) (-870)
				(-870) (-870) (-870) (-870)
				(-870) (-870) (-870) (-870)
				(-870) (-870) (-870) (-870)
				(-870) (-870) (-870) (-870)
				(-870) (-870) (-870) (-870)
				(-870) (-870) (-870) (-870)
				(-870) (-870) (-870) (-870)
				(-870) (-870) (-870) (-870)
				(-870) (-870) (-870) (-870)
				(-870) (-870) (-870) (-870)
				(-870) (-870) (-870) (-870)
				(-870) (-870) (-870) (-870)
				(-870) (-870) (-870) (-870)
				(-870) (-870) (-870) (-870)
				(-870) (-870) (-870) (-870)
				(-870) (-870) (-870) (-870)
				(-870) (-870) (-870) (-870)
				(-870) (-870) (-870) (-870)
				(-870) (-870) (-870) (-870)
				(-870) (-870) (-870) (-870)
				(-870) (-870) (-870) (-870)>;

			PS_Config_Lmt_PenRingX_FW_Diff_P = <
				870 870 870 870 870 870 870 870 870 870 870 870 870 870 870 870 870 870 870 870 870 870 870 870 870 870 870 870 870 870 870 870
				870 870 870 870 870 870 870 870 870 870 870 870 870 870 870 870 870 870 870 870 870 870 870 870 870 870 870 870 870 870 870 870
				870 870 870 870 870 870 870 870 870 870 870 870 870 870 870 870 870 870 870 870 870 870 870 870 870 870 870 870 870 870 870 870
				870 870 870 870 870 870 870 870 870 870 870 870 870 870 870 870 870 870 870 870 870 870 870 870 870 870 870 870 870 870 870 870
				870 870 870 870 870 870 870 870 870 870 870 870 870 870 870 870 870 870 870 870 870 870 870 870 870 870 870 870 870 870 870 870
				870 870 870 870 870 870 870 870 870 870 870 870 870 870 870 870 870 870 870 870 870 870 870 870 870 870 870 870 870 870 870 870>;

			PS_Config_Lmt_PenRingX_FW_Diff_N = <
				(-870) (-870) (-870) (-870) (-870) (-870) (-870) (-870) (-870) (-870) (-870) (-870) (-870) (-870) (-870) (-870) (-870) (-870) (-870) (-870) (-870) (-870) (-870) (-870) (-870) (-870) (-870) (-870) (-870) (-870) (-870) (-870)
				(-870) (-870) (-870) (-870) (-870) (-870) (-870) (-870) (-870) (-870) (-870) (-870) (-870) (-870) (-870) (-870) (-870) (-870) (-870) (-870) (-870) (-870) (-870) (-870) (-870) (-870) (-870) (-870) (-870) (-870) (-870) (-870)
				(-870) (-870) (-870) (-870) (-870) (-870) (-870) (-870) (-870) (-870) (-870) (-870) (-870) (-870) (-870) (-870) (-870) (-870) (-870) (-870) (-870) (-870) (-870) (-870) (-870) (-870) (-870) (-870) (-870) (-870) (-870) (-870)
				(-870) (-870) (-870) (-870) (-870) (-870) (-870) (-870) (-870) (-870) (-870) (-870) (-870) (-870) (-870) (-870) (-870) (-870) (-870) (-870) (-870) (-870) (-870) (-870) (-870) (-870) (-870) (-870) (-870) (-870) (-870) (-870)
				(-870) (-870) (-870) (-870) (-870) (-870) (-870) (-870) (-870) (-870) (-870) (-870) (-870) (-870) (-870) (-870) (-870) (-870) (-870) (-870) (-870) (-870) (-870) (-870) (-870) (-870) (-870) (-870) (-870) (-870) (-870) (-870)
				(-870) (-870) (-870) (-870) (-870) (-870) (-870) (-870) (-870) (-870) (-870) (-870) (-870) (-870) (-870) (-870) (-870) (-870) (-870) (-870) (-870) (-870) (-870) (-870) (-870) (-870) (-870) (-870) (-870) (-870) (-870) (-870)>;

			PS_Config_Lmt_PenRingY_FW_Diff_P = <
				870 870 870 870
				870 870 870 870
				870 870 870 870
				870 870 870 870
				870 870 870 870
				870 870 870 870
				870 870 870 870
				870 870 870 870
				870 870 870 870
				870 870 870 870
				870 870 870 870
				870 870 870 870
				870 870 870 870
				870 870 870 870
				870 870 870 870
				870 870 870 870
				870 870 870 870
				870 870 870 870
				870 870 870 870
				870 870 870 870
				870 870 870 870
				870 870 870 870
				870 870 870 870
				870 870 870 870
				870 870 870 870
				870 870 870 870
				870 870 870 870
				870 870 870 870
				870 870 870 870
				870 870 870 870
				870 870 870 870
				870 870 870 870
				870 870 870 870
				870 870 870 870
				870 870 870 870
				870 870 870 870
				870 870 870 870
				870 870 870 870
				870 870 870 870
				870 870 870 870
				870 870 870 870
				870 870 870 870
				870 870 870 870
				870 870 870 870
				870 870 870 870
				870 870 870 870
				870 870 870 870
				870 870 870 870
				870 870 870 870
				870 870 870 870>;

			PS_Config_Lmt_PenRingY_FW_Diff_N = <
				(-870) (-870) (-870) (-870)
				(-870) (-870) (-870) (-870)
				(-870) (-870) (-870) (-870)
				(-870) (-870) (-870) (-870)
				(-870) (-870) (-870) (-870)
				(-870) (-870) (-870) (-870)
				(-870) (-870) (-870) (-870)
				(-870) (-870) (-870) (-870)
				(-870) (-870) (-870) (-870)
				(-870) (-870) (-870) (-870)
				(-870) (-870) (-870) (-870)
				(-870) (-870) (-870) (-870)
				(-870) (-870) (-870) (-870)
				(-870) (-870) (-870) (-870)
				(-870) (-870) (-870) (-870)
				(-870) (-870) (-870) (-870)
				(-870) (-870) (-870) (-870)
				(-870) (-870) (-870) (-870)
				(-870) (-870) (-870) (-870)
				(-870) (-870) (-870) (-870)
				(-870) (-870) (-870) (-870)
				(-870) (-870) (-870) (-870)
				(-870) (-870) (-870) (-870)
				(-870) (-870) (-870) (-870)
				(-870) (-870) (-870) (-870)
				(-870) (-870) (-870) (-870)
				(-870) (-870) (-870) (-870)
				(-870) (-870) (-870) (-870)
				(-870) (-870) (-870) (-870)
				(-870) (-870) (-870) (-870)
				(-870) (-870) (-870) (-870)
				(-870) (-870) (-870) (-870)
				(-870) (-870) (-870) (-870)
				(-870) (-870) (-870) (-870)
				(-870) (-870) (-870) (-870)
				(-870) (-870) (-870) (-870)
				(-870) (-870) (-870) (-870)
				(-870) (-870) (-870) (-870)
				(-870) (-870) (-870) (-870)
				(-870) (-870) (-870) (-870)
				(-870) (-870) (-870) (-870)
				(-870) (-870) (-870) (-870)
				(-870) (-870) (-870) (-870)
				(-870) (-870) (-870) (-870)
				(-870) (-870) (-870) (-870)
				(-870) (-870) (-870) (-870)
				(-870) (-870) (-870) (-870)
				(-870) (-870) (-870) (-870)
				(-870) (-870) (-870) (-870)
				(-870) (-870) (-870) (-870)>;

			PS_Config_Diff_Test_Frame = <50>;
		};
	};
};

/* Huaqin modify for HQ-152282 by zhangjiangbin at 2021/08/23 end */

/* TOUCH end */
